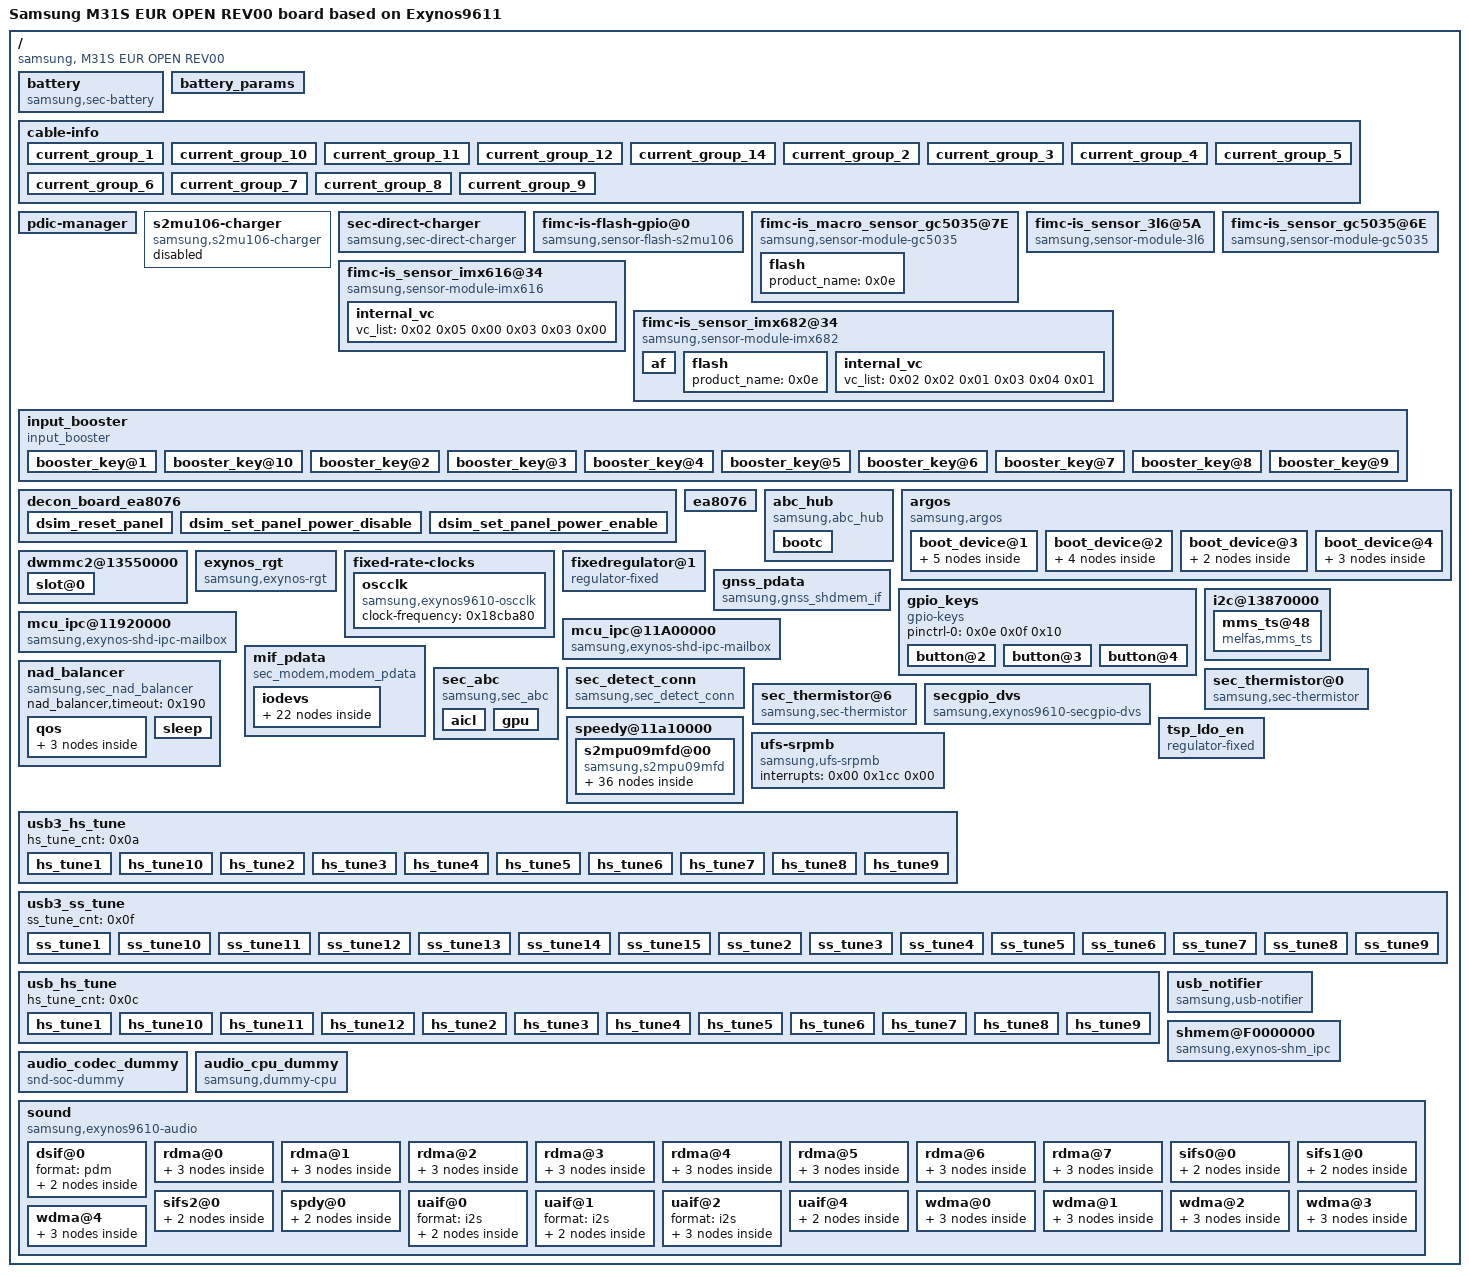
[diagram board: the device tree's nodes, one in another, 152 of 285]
/dts-v1/;

/ {
	compatible = "samsung, M31S EUR OPEN REV00\0samsung,EXYNOS9611";
	dtbo-hw_rev = <0x00>;
	dtbo-hw_rev_end = <0xff>;

	__fixups__ {
		abox = "/fragment@sound/__overlay__/sound:samsung,codec:0\0/fragment@sound/__overlay__/sound/rdma@0/cpu:sound-dai:0\0/fragment@sound/__overlay__/sound/rdma@1/cpu:sound-dai:0\0/fragment@sound/__overlay__/sound/rdma@2/cpu:sound-dai:0\0/fragment@sound/__overlay__/sound/rdma@3/cpu:sound-dai:0\0/fragment@sound/__overlay__/sound/rdma@4/cpu:sound-dai:0\0/fragment@sound/__overlay__/sound/rdma@5/cpu:sound-dai:0\0/fragment@sound/__overlay__/sound/rdma@6/cpu:sound-dai:0\0/fragment@sound/__overlay__/sound/rdma@7/cpu:sound-dai:0\0/fragment@sound/__overlay__/sound/wdma@0/cpu:sound-dai:0\0/fragment@sound/__overlay__/sound/wdma@1/cpu:sound-dai:0\0/fragment@sound/__overlay__/sound/wdma@2/cpu:sound-dai:0\0/fragment@sound/__overlay__/sound/wdma@3/cpu:sound-dai:0\0/fragment@sound/__overlay__/sound/wdma@4/cpu:sound-dai:0\0/fragment@sound/__overlay__/sound/sifs0@0/cpu:sound-dai:0\0/fragment@sound/__overlay__/sound/sifs1@0/cpu:sound-dai:0\0/fragment@sound/__overlay__/sound/sifs2@0/cpu:sound-dai:0\0/fragment@15:target:0";
		abox_bt = "/fragment@sound/__overlay__/sound:samsung,aux:4";
		abox_dsif = "/fragment@sound/__overlay__/sound:samsung,codec:20\0/fragment@sound/__overlay__/sound/dsif@0/cpu:sound-dai:0";
		abox_effect = "/fragment@sound/__overlay__/sound:samsung,aux:0";
		abox_rdma_0 = "/fragment@sound/__overlay__/sound/rdma@0/platform:sound-dai:0";
		abox_rdma_1 = "/fragment@sound/__overlay__/sound/rdma@1/platform:sound-dai:0";
		abox_rdma_2 = "/fragment@sound/__overlay__/sound/rdma@2/platform:sound-dai:0";
		abox_rdma_3 = "/fragment@sound/__overlay__/sound/rdma@3/platform:sound-dai:0";
		abox_rdma_4 = "/fragment@sound/__overlay__/sound/rdma@4/platform:sound-dai:0";
		abox_rdma_5 = "/fragment@sound/__overlay__/sound/rdma@5/platform:sound-dai:0";
		abox_rdma_6 = "/fragment@sound/__overlay__/sound/rdma@6/platform:sound-dai:0";
		abox_rdma_7 = "/fragment@sound/__overlay__/sound/rdma@7/platform:sound-dai:0";
		abox_spdy = "/fragment@sound/__overlay__/sound:samsung,codec:24\0/fragment@sound/__overlay__/sound/spdy@0/cpu:sound-dai:0";
		abox_synchronized_ipc = "/fragment@sound/__overlay__/sound/uaif@2/platform:sound-dai:0";
		abox_uaif_0 = "/fragment@sound/__overlay__/sound:samsung,codec:4\0/fragment@sound/__overlay__/sound/uaif@0/cpu:sound-dai:0";
		abox_uaif_1 = "/fragment@sound/__overlay__/sound:samsung,codec:8\0/fragment@sound/__overlay__/sound/uaif@1/cpu:sound-dai:0";
		abox_uaif_2 = "/fragment@sound/__overlay__/sound:samsung,codec:12\0/fragment@sound/__overlay__/sound/uaif@2/cpu:sound-dai:0";
		abox_uaif_4 = "/fragment@sound/__overlay__/sound:samsung,codec:16\0/fragment@sound/__overlay__/sound/uaif@4/cpu:sound-dai:0";
		abox_wdma_0 = "/fragment@sound/__overlay__/sound/wdma@0/platform:sound-dai:0";
		abox_wdma_1 = "/fragment@sound/__overlay__/sound/wdma@1/platform:sound-dai:0";
		abox_wdma_2 = "/fragment@sound/__overlay__/sound/wdma@2/platform:sound-dai:0";
		abox_wdma_3 = "/fragment@sound/__overlay__/sound/wdma@3/platform:sound-dai:0";
		abox_wdma_4 = "/fragment@sound/__overlay__/sound/wdma@4/platform:sound-dai:0";
		android_q_fstab = "/fragment@23:target:0";
		chosen = "/fragment@47:target:0";
		clock = "/fragment@sound/__overlay__/sound:clocks:0\0/fragment@52/__overlay__:clocks:0\0/fragment@52/__overlay__:clocks:8\0/fragment@55/__overlay__/sec-nfc@27:clocks:0";
		contexthub_0 = "/fragment@52:target:0";
		decon_f = "/fragment@1:target:0";
		dsim_0 = "/fragment@0:target:0";
		exynos_adc = "/fragment@battery/__overlay__/battery:io-channels:0\0/fragment@battery/__overlay__/battery:io-channels:8\0/fragment@model/__overlay__/sec_thermistor@0:io-channels:0\0/fragment@model/__overlay__/sec_thermistor@6:io-channels:0";
		fimc_is = "/fragment@2:target:0";
		fimc_is_mclk0_fn = "/fragment@camera/__overlay__/fimc-is_sensor_imx682@34:pinctrl-1:0\0/fragment@camera/__overlay__/fimc-is_sensor_gc5035@6E:pinctrl-2:0";
		fimc_is_mclk0_out = "/fragment@camera/__overlay__/fimc-is_sensor_imx682@34:pinctrl-0:0\0/fragment@camera/__overlay__/fimc-is_sensor_gc5035@6E:pinctrl-1:0\0/fragment@2/__overlay__:pinctrl-0:0";
		fimc_is_mclk1_fn = "/fragment@camera/__overlay__/fimc-is_sensor_imx616@34:pinctrl-2:0";
		fimc_is_mclk1_out = "/fragment@camera/__overlay__/fimc-is_sensor_imx616@34:pinctrl-1:0\0/fragment@2/__overlay__:pinctrl-0:4";
		fimc_is_mclk2_fn = "/fragment@camera/__overlay__/fimc-is_sensor_3l6@5A:pinctrl-2:0\0/fragment@camera/__overlay__/fimc-is_macro_sensor_gc5035@7E:pinctrl-2:0";
		fimc_is_mclk2_out = "/fragment@camera/__overlay__/fimc-is_sensor_3l6@5A:pinctrl-1:0\0/fragment@camera/__overlay__/fimc-is_macro_sensor_gc5035@7E:pinctrl-1:0\0/fragment@2/__overlay__:pinctrl-0:8";
		fimc_is_sensor0 = "/fragment@10:target:0";
		fimc_is_sensor1 = "/fragment@11:target:0";
		fimc_is_sensor2 = "/fragment@12:target:0";
		fimc_is_sensor3 = "/fragment@13:target:0";
		fimc_is_sensor4 = "/fragment@14:target:0";
		fmp_0 = "/fragment@31:target:0";
		gnss_reserved = "/fragment@model/__overlay__/gnss_pdata:memory-region:0";
		gpa0 = "/fragment@lcd/__overlay__/decon_board_ea8076:gpio_det:0\0/fragment@lcd/__overlay__/decon_board_ea8076:gpio_con:0\0/fragment@model/__overlay__/i2c@13870000/mms_ts@48:melfas,irq-gpio:0\0/fragment@model/__overlay__/sec_detect_conn:sec,det_conn_gpios:0\0/fragment@62/__overlay__/etspi-spi@0:etspi-drdyPin:0\0/fragment@63/__overlay__/isg5320a@28:interrupt-parent:0\0/fragment@63/__overlay__/isg5320a@28:isg5320a,irq-gpio:0";
		gpa1 = "/fragment@lcd/__overlay__/decon_board_ea8076:gpio_err:0\0/fragment@camera/__overlay__/fimc-is-flash-gpio@0:torch-gpio:0\0/fragment@9/__overlay__/s2mu106@3D/flash_led:torch-gpio:0\0/fragment@17/__overlay__/rt5665@1b:interrupt-parent:0\0/fragment@20/__overlay__/sm5440@63:sm5440,irq-gpio:0\0/fragment@model/__overlay__/gpio_keys/button@2:gpios:0\0/fragment@model/__overlay__/gpio_keys/button@3:gpios:0\0/fragment@model/__overlay__/gpio_keys/button@4:gpios:0\0/fragment@55/__overlay__/sec-nfc@27:interrupt-parent:0\0/fragment@55/__overlay__/sec-nfc@27:sec-nfc,irq-gpio:0";
		gpa2 = "/fragment@lcd/__overlay__/decon_board_ea8076:gpio_pcd:0\0/fragment@model/__overlay__/speedy@11a10000/s2mpu09mfd@00:s2mpu09,irq-gpio:0\0/fragment@model/__overlay__/speedy@11a10000/s2mpu09mfd@00:interrupt-parent:0\0/fragment@model/__overlay__/dwmmc2@13550000:card-detect:0\0/fragment@48/__overlay__/usbpd-s2mu106@3C:usbpd,usbpd_int:0\0/fragment@49/__overlay__/s2mu106@3D:s2mu106,irq-gpio:0\0/fragment@49/__overlay__/s2mu106@3A/s2mu106-haptic:haptic,motor_en:0\0/fragment@55/__overlay__/sec-nfc@27:sec-nfc,clk_req-gpio:0\0/fragment@63/__overlay__/isg5320a_sub@2C:interrupt-parent:0\0/fragment@63/__overlay__/isg5320a_sub@2C:isg5320a_sub,irq-gpio:0";
		gpc0 = "/fragment@3/__overlay__:gpios:0\0/fragment@3/__overlay__:gpios:12\0/fragment@4/__overlay__:gpios:0\0/fragment@4/__overlay__:gpios:12\0/fragment@5/__overlay__:gpios:0\0/fragment@5/__overlay__:gpios:12\0/fragment@6/__overlay__:gpios:0\0/fragment@6/__overlay__:gpios:12";
		gpc1 = "/fragment@7/__overlay__:gpios:0\0/fragment@7/__overlay__:gpios:12\0/fragment@8/__overlay__:gpios:0\0/fragment@8/__overlay__:gpios:12";
		gpc2 = "/fragment@camera/__overlay__/fimc-is_sensor_imx682@34:gpio_mclk:0\0/fragment@camera/__overlay__/fimc-is_sensor_gc5035@6E:gpio_mclk:0\0/fragment@camera/__overlay__/fimc-is_sensor_3l6@5A:gpio_mclk:0\0/fragment@camera/__overlay__/fimc-is_macro_sensor_gc5035@7E:gpio_mclk:0\0/fragment@camera/__overlay__/fimc-is_sensor_imx616@34:gpio_mclk:0";
		gpg0 = "/fragment@camera/__overlay__/fimc-is_sensor_imx682@34:gpio_ldo_en:0\0/fragment@camera/__overlay__/fimc-is-flash-gpio@0:flash-gpio:0\0/fragment@camera/__overlay__/fimc-is_sensor_gc5035@6E:gpio_reset:0\0/fragment@camera/__overlay__/fimc-is_macro_sensor_gc5035@7E:gpio_reset:0\0/fragment@9/__overlay__/s2mu106@3D/flash_led:flash-gpio:0\0/fragment@55/__overlay__/sec-nfc@27:sec-nfc,ven-gpio:0\0/fragment@55/__overlay__/sec-nfc@27:sec-nfc,check_nfc:0";
		gpg1 = "/fragment@lcd/__overlay__/decon_board_ea8076:gpio_lcd_rst:0\0/fragment@lcd/__overlay__/decon_board_ea8076:gpio_lcd_en_1p8:0\0/fragment@camera/__overlay__/fimc-is_sensor_imx682@34:gpio_reset:0\0/fragment@camera/__overlay__/fimc-is_sensor_3l6@5A:gpio_reset:0\0/fragment@camera/__overlay__/fimc-is_sensor_3l6@5A:gpio_ldo_en:0\0/fragment@camera/__overlay__/fimc-is_sensor_imx616@34:gpio_reset:0\0/fragment@55/__overlay__/sec-nfc@27:sec-nfc,firm-gpio:0";
		gpg2 = "/fragment@lcd/__overlay__/decon_board_ea8076:gpio_lcd_en_3p0:0";
		gpg3 = "/fragment@model/__overlay__/mif_pdata:gpios:0\0/fragment@model/__overlay__/mif_pdata:gpios:12\0/fragment@model/__overlay__/mif_pdata:gpios:24\0/fragment@model/__overlay__/mif_pdata:gpios:36\0/fragment@model/__overlay__/tsp_ldo_en:gpio:0\0/fragment@62/__overlay__/etspi-spi@0:etspi-sleepPin:0";
		gpm20 = "/fragment@21/__overlay__/s2mu106-fuelgauge@3B:fuelgauge,fuel_int:0";
		gpm21 = "/fragment@52/__overlay__:sensor-ldo-en:0";
		gpm22 = "/fragment@camera/__overlay__/fimc-is_macro_sensor_gc5035@7E:gpio_cam_a2p8_1p2_en:0";
		gpp1 = "/fragment@model/__overlay__/i2c@13870000/mms_ts@48:melfas,scl-gpio:0\0/fragment@model/__overlay__/i2c@13870000/mms_ts@48:melfas,sda-gpio:0";
		gpp2 = "/fragment@62/__overlay__/etspi-spi@0/controller-data:cs-gpio:0";
		hsi2c12_bus = "/fragment@3/__overlay__:pinctrl-0:0\0/fragment@3/__overlay__:pinctrl-1:0\0/fragment@3/__overlay__:pinctrl-2:0";
		hsi2c13_bus = "/fragment@4/__overlay__:pinctrl-0:0\0/fragment@4/__overlay__:pinctrl-1:0\0/fragment@4/__overlay__:pinctrl-2:0";
		hsi2c14_bus = "/fragment@5/__overlay__:pinctrl-0:0\0/fragment@5/__overlay__:pinctrl-1:0\0/fragment@5/__overlay__:pinctrl-2:0";
		hsi2c15_bus = "/fragment@6/__overlay__:pinctrl-0:0\0/fragment@6/__overlay__:pinctrl-1:0\0/fragment@6/__overlay__:pinctrl-2:0";
		hsi2c16_bus = "/fragment@7/__overlay__:pinctrl-0:0\0/fragment@7/__overlay__:pinctrl-1:0\0/fragment@7/__overlay__:pinctrl-2:0";
		hsi2c17_bus = "/fragment@8/__overlay__:pinctrl-0:0\0/fragment@8/__overlay__:pinctrl-1:0\0/fragment@8/__overlay__:pinctrl-2:0";
		hsi2c_12 = "/fragment@3:target:0";
		hsi2c_13 = "/fragment@4:target:0";
		hsi2c_14 = "/fragment@5:target:0";
		hsi2c_15 = "/fragment@6:target:0";
		hsi2c_16 = "/fragment@7:target:0";
		hsi2c_17 = "/fragment@8:target:0";
		hsi2c_3 = "/fragment@16:target:0";
		hsi2c_6 = "/fragment@55:target:0";
		i2c_0 = "/fragment@21:target:0\0/fragment@48:target:0";
		i2c_1 = "/fragment@9:target:0\0/fragment@20:target:0\0/fragment@49:target:0";
		i2c_3 = "/fragment@50:target:0";
		i2c_5 = "/fragment@63:target:0";
		i2c_6 = "/fragment@17:target:0";
		mipi_phy_csis_m2s4s4s2 = "/fragment@11/__overlay__:phys:0\0/fragment@13/__overlay__:phys:0";
		pdma0 = "/fragment@62/__overlay__:dmas:0\0/fragment@62/__overlay__:dmas:8";
		pinctrl_0 = "/fragment@19:target:0\0/fragment@29:target:0\0/fragment@53:target:0\0/fragment@56:target:0\0/fragment@60:target:0\0/fragment@64:target:0";
		pinctrl_1 = "/fragment@18:target:0\0/fragment@57:target:0";
		pinctrl_2 = "/fragment@58:target:0";
		pinctrl_4 = "/fragment@30:target:0\0/fragment@54:target:0\0/fragment@59:target:0\0/fragment@61:target:0";
		reserved_memory = "/fragment@51:target:0";
		sd2_bus1 = "/fragment@model/__overlay__/dwmmc2@13550000:pinctrl-0:8";
		sd2_bus4 = "/fragment@model/__overlay__/dwmmc2@13550000:pinctrl-0:12";
		sd2_clk = "/fragment@model/__overlay__/dwmmc2@13550000:pinctrl-0:0";
		sd2_clk_fast_slew_rate_1x = "/fragment@model/__overlay__/dwmmc2@13550000:pinctrl-1:0";
		sd2_clk_fast_slew_rate_2x = "/fragment@model/__overlay__/dwmmc2@13550000:pinctrl-2:0";
		sd2_clk_fast_slew_rate_3x = "/fragment@model/__overlay__/dwmmc2@13550000:pinctrl-3:0";
		sd2_clk_fast_slew_rate_4x = "/fragment@model/__overlay__/dwmmc2@13550000:pinctrl-4:0";
		sd2_cmd = "/fragment@model/__overlay__/dwmmc2@13550000:pinctrl-0:4";
		serial_0 = "/fragment@28:target:0";
		shared_meta = "/fragment@22:target:0";
		spi_7 = "/fragment@62:target:0";
		udc = "/fragment@model/__overlay__/usb_notifier:udc:0\0/fragment@24:target:0";
		usbdrd3_phy = "/fragment@27:target:0";
		usbdrd_dwc3 = "/fragment@25:target:0";
		usbdrd_phy = "/fragment@26:target:0";
		usi_0_cmgp = "/fragment@34:target:0";
		usi_0_cmgp_i2c = "/fragment@35:target:0";
		usi_0_shub = "/fragment@32:target:0";
		usi_0_shub_i2c = "/fragment@33:target:0";
		usi_1_cmgp = "/fragment@36:target:0";
		usi_1_cmgp_i2c = "/fragment@37:target:0";
		usi_2_cmgp = "/fragment@38:target:0";
		usi_2_cmgp_i2c = "/fragment@39:target:0";
		usi_3_cmgp = "/fragment@40:target:0";
		usi_3_cmgp_i2c = "/fragment@41:target:0";
		usi_4_cmgp = "/fragment@42:target:0";
		usi_4_cmgp_i2c = "/fragment@43:target:0";
		usi_peri_spi_1 = "/fragment@46:target:0";
		usi_peri_usi_0 = "/fragment@44:target:0";
		usi_peri_usi_0_i2c = "/fragment@45:target:0";
		xclkout0 = "/fragment@sound/__overlay__/sound:pinctrl-0:0";
		xclkout1 = "/fragment@55/__overlay__/sec-nfc@27:pinctrl-0:8";
	};

	__local_fixups__ {

		fragment@0 {

			__overlay__ {
				lcd_info = <0x00>;
			};
		};

		fragment@17 {

			__overlay__ {

				rt5665@1b {
					pinctrl-0 = <0x00>;
					realtek,regulator_1v8 = <0x00>;
					realtek,regulator_3v3 = <0x00>;
				};
			};
		};

		fragment@20 {

			__overlay__ {

				sm5440@63 {
					pinctrl-0 = <0x00>;
				};
			};
		};

		fragment@21 {

			__overlay__ {

				s2mu106-fuelgauge@3B {
					pinctrl-0 = <0x00>;
				};
			};
		};

		fragment@26 {

			__overlay__ {
				hs_tune_param = <0x00>;
			};
		};

		fragment@27 {

			__overlay__ {
				hs_tune_param = <0x00>;
				ss_tune_param = <0x00>;
			};
		};

		fragment@48 {

			__overlay__ {

				usbpd-s2mu106@3C {
					pinctrl-0 = <0x00>;
				};
			};
		};

		fragment@49 {

			__overlay__ {

				s2mu106@3A {

					s2mu106-haptic {
						pinctrl-0 = <0x00>;
					};
				};

				s2mu106@3D {
					pinctrl-0 = <0x00>;
				};
			};
		};

		fragment@55 {

			__overlay__ {

				sec-nfc@27 {
					pinctrl-0 = <0x00 0x04 0x0c 0x10>;
					pinctrl-1 = <0x00 0x04 0x08 0x0c>;
				};
			};
		};

		fragment@56 {

			__overlay__ {
				pinctrl-0 = <0x00>;
			};
		};

		fragment@57 {

			__overlay__ {
				pinctrl-0 = <0x00>;
				pinctrl-1 = <0x00>;
			};
		};

		fragment@58 {

			__overlay__ {
				pinctrl-0 = <0x00>;
			};
		};

		fragment@59 {

			__overlay__ {
				pinctrl-0 = <0x00>;
				pinctrl-1 = <0x00>;
			};
		};

		fragment@62 {

			__overlay__ {

				etspi-spi@0 {
					pinctrl-0 = <0x00 0x04>;
					pinctrl-1 = <0x00 0x04 0x08 0x0c 0x10>;
					pinctrl-2 = <0x00 0x04 0x08>;
					pinctrl-3 = <0x00>;
					pinctrl-4 = <0x00>;
				};
			};
		};

		fragment@63 {

			__overlay__ {

				isg5320a@28 {
					pinctrl-0 = <0x00>;
				};

				isg5320a_sub@2C {
					pinctrl-0 = <0x00>;
				};
			};
		};

		fragment@lcd {

			__overlay__ {

				ea8076 {
					decon_board = <0x00>;
				};
			};
		};

		fragment@model {

			__overlay__ {

				dwmmc2@13550000 {
					pinctrl-0 = <0x10>;
				};

				gnss_pdata {
					mbox_info = <0x00>;
				};

				gpio_keys {
					pinctrl-0 = <0x00 0x04 0x08>;
				};

				i2c@13870000 {

					mms_ts@48 {
						pinctrl-0 = <0x00>;
						pinctrl-1 = <0x00>;
					};
				};

				sec_detect_conn {
					pinctrl-0 = <0x00>;
				};

				speedy@11a10000 {

					s2mpu09mfd@00 {
						pinctrl-0 = <0x00 0x04>;
					};
				};
			};
		};

		fragment@sound {

			__overlay__ {

				sound {

					dsif@0 {

						codec {
							sound-dai = <0x00>;
						};
					};

					rdma@0 {

						codec {
							sound-dai = <0x00>;
						};
					};

					rdma@1 {

						codec {
							sound-dai = <0x00>;
						};
					};

					rdma@2 {

						codec {
							sound-dai = <0x00>;
						};
					};

					rdma@3 {

						codec {
							sound-dai = <0x00>;
						};
					};

					rdma@4 {

						codec {
							sound-dai = <0x00>;
						};
					};

					rdma@5 {

						codec {
							sound-dai = <0x00>;
						};
					};

					rdma@6 {

						codec {
							sound-dai = <0x00>;
						};
					};

					rdma@7 {

						codec {
							sound-dai = <0x00>;
						};
					};

					sifs0@0 {

						codec {
							sound-dai = <0x00>;
						};
					};

					sifs1@0 {

						codec {
							sound-dai = <0x00>;
						};
					};

					sifs2@0 {

						codec {
							sound-dai = <0x00>;
						};
					};

					spdy@0 {

						codec {
							sound-dai = <0x00>;
						};
					};

					uaif@0 {

						codec {
							sound-dai = <0x00>;
						};
					};

					uaif@1 {

						codec {
							sound-dai = <0x00>;
						};
					};

					uaif@2 {

						codec {
							sound-dai = <0x00>;
						};
					};

					uaif@4 {

						codec {
							sound-dai = <0x00>;
						};
					};

					wdma@0 {

						codec {
							sound-dai = <0x00>;
						};
					};

					wdma@1 {

						codec {
							sound-dai = <0x00>;
						};
					};

					wdma@2 {

						codec {
							sound-dai = <0x00>;
						};
					};

					wdma@3 {

						codec {
							sound-dai = <0x00>;
						};
					};

					wdma@4 {

						codec {
							sound-dai = <0x00>;
						};
					};
				};
			};
		};
	};

	__symbols__ {
		V_SYS = "/fragment@model/__overlay__/fixedregulator@1";
		__ldo1_reg = "/fragment@50/__overlay__/s2mpb03@56/regulators/s2mpb03-ldo1";
		__ldo2_reg = "/fragment@50/__overlay__/s2mpb03@56/regulators/s2mpb03-ldo2";
		__ldo3_reg = "/fragment@50/__overlay__/s2mpb03@56/regulators/s2mpb03-ldo3";
		__ldo4_reg = "/fragment@50/__overlay__/s2mpb03@56/regulators/s2mpb03-ldo4";
		__ldo5_reg = "/fragment@50/__overlay__/s2mpb03@56/regulators/s2mpb03-ldo5";
		__ldo6_reg = "/fragment@50/__overlay__/s2mpb03@56/regulators/s2mpb03-ldo6";
		__ldo7_reg = "/fragment@50/__overlay__/s2mpb03@56/regulators/s2mpb03-ldo7";
		attn_input = "/fragment@29/__overlay__/attn-input";
		attn_irq = "/fragment@29/__overlay__/attn-irq";
		b1_reg = "/fragment@model/__overlay__/speedy@11a10000/s2mpu09mfd@00/regulators/BUCK1";
		b2_reg = "/fragment@model/__overlay__/speedy@11a10000/s2mpu09mfd@00/regulators/BUCK2";
		b3_reg = "/fragment@model/__overlay__/speedy@11a10000/s2mpu09mfd@00/regulators/BUCK3";
		b4_reg = "/fragment@model/__overlay__/speedy@11a10000/s2mpu09mfd@00/regulators/BUCK4";
		b5_reg = "/fragment@model/__overlay__/speedy@11a10000/s2mpu09mfd@00/regulators/BUCK5";
		b6_reg = "/fragment@model/__overlay__/speedy@11a10000/s2mpu09mfd@00/regulators/BUCK6";
		b7_reg = "/fragment@model/__overlay__/speedy@11a10000/s2mpu09mfd@00/regulators/BUCK7";
		b8_reg = "/fragment@model/__overlay__/speedy@11a10000/s2mpu09mfd@00/regulators/BUCK8";
		b9_reg = "/fragment@model/__overlay__/speedy@11a10000/s2mpu09mfd@00/regulators/BUCK9";
		btp_irq = "/fragment@60/__overlay__/btp-irq";
		btp_irq_sleep = "/fragment@60/__overlay__/btp-irq-sleep";
		btp_rst = "/fragment@61/__overlay__/btp-rst";
		codec_irq = "/fragment@29/__overlay__/codec_irq";
		dc_irq = "/fragment@19/__overlay__/dc-irq";
		decon_board_ea8076 = "/fragment@lcd/__overlay__/decon_board_ea8076";
		dummy_audio_codec = "/fragment@sound/__overlay__/audio_codec_dummy";
		dummy_audio_cpu = "/fragment@sound/__overlay__/audio_cpu_dummy";
		dwmmc2_cd_ext_irq = "/fragment@29/__overlay__/dwmmc2_cd_ext_irq";
		ea8076 = "/fragment@lcd/__overlay__/ea8076";
		ext_bin_0 = "/fragment@15/__overlay__/ext_bin@0";
		ext_bin_1 = "/fragment@15/__overlay__/ext_bin@1";
		ext_bin_2 = "/fragment@15/__overlay__/ext_bin@2";
		ext_bin_4 = "/fragment@15/__overlay__/ext_bin@4";
		ext_bin_5 = "/fragment@15/__overlay__/ext_bin@5";
		fimc_is_flash_gpio = "/fragment@camera/__overlay__/fimc-is-flash-gpio@0";
		fimc_is_macro_module_gc5035 = "/fragment@camera/__overlay__/fimc-is_macro_sensor_gc5035@7E";
		fimc_is_module_gc5035 = "/fragment@camera/__overlay__/fimc-is_sensor_gc5035@6E";
		fimc_is_sensor_3l6 = "/fragment@camera/__overlay__/fimc-is_sensor_3l6@5A";
		fimc_is_sensor_imx616 = "/fragment@camera/__overlay__/fimc-is_sensor_imx616@34";
		fimc_is_sensor_imx682 = "/fragment@camera/__overlay__/fimc-is_sensor_imx682@34";
		fuel_irq = "/fragment@18/__overlay__/fuel-irq";
		grip_int = "/fragment@64/__overlay__/grip-int";
		grip_sub_int = "/fragment@64/__overlay__/grip-sub-int";
		i2c_4 = "/fragment@model/__overlay__/i2c@13870000";
		if_pmic_irq = "/fragment@29/__overlay__/if-pmic-irq";
		initial0 = "/fragment@56/__overlay__/initial-state";
		initial1 = "/fragment@57/__overlay__/initial-state";
		initial4 = "/fragment@59/__overlay__/initial-state";
		key_power = "/fragment@29/__overlay__/key-power";
		key_voldown = "/fragment@29/__overlay__/key-voldown";
		key_volup = "/fragment@29/__overlay__/key-volup";
		l10_reg = "/fragment@model/__overlay__/speedy@11a10000/s2mpu09mfd@00/regulators/LDO10";
		l11_reg = "/fragment@model/__overlay__/speedy@11a10000/s2mpu09mfd@00/regulators/LDO11";
		l12_reg = "/fragment@model/__overlay__/speedy@11a10000/s2mpu09mfd@00/regulators/LDO12";
		l13_reg = "/fragment@model/__overlay__/speedy@11a10000/s2mpu09mfd@00/regulators/LDO13";
		l14_reg = "/fragment@model/__overlay__/speedy@11a10000/s2mpu09mfd@00/regulators/LDO14";
		l1_reg = "/fragment@model/__overlay__/speedy@11a10000/s2mpu09mfd@00/regulators/LDO1";
		l2_reg = "/fragment@model/__overlay__/speedy@11a10000/s2mpu09mfd@00/regulators/LDO2";
		l33_reg = "/fragment@model/__overlay__/speedy@11a10000/s2mpu09mfd@00/regulators/LDO33";
		l34_reg = "/fragment@model/__overlay__/speedy@11a10000/s2mpu09mfd@00/regulators/LDO34";
		l35_reg = "/fragment@model/__overlay__/speedy@11a10000/s2mpu09mfd@00/regulators/LDO35";
		l36_reg = "/fragment@model/__overlay__/speedy@11a10000/s2mpu09mfd@00/regulators/LDO36";
		l37_reg = "/fragment@model/__overlay__/speedy@11a10000/s2mpu09mfd@00/regulators/LDO37";
		l38_reg = "/fragment@model/__overlay__/speedy@11a10000/s2mpu09mfd@00/regulators/LDO38";
		l39_reg = "/fragment@model/__overlay__/speedy@11a10000/s2mpu09mfd@00/regulators/LDO39";
		l3_reg = "/fragment@model/__overlay__/speedy@11a10000/s2mpu09mfd@00/regulators/LDO3";
		l40_reg = "/fragment@model/__overlay__/speedy@11a10000/s2mpu09mfd@00/regulators/LDO40";
		l41_reg = "/fragment@model/__overlay__/speedy@11a10000/s2mpu09mfd@00/regulators/LDO41";
		l42_reg = "/fragment@model/__overlay__/speedy@11a10000/s2mpu09mfd@00/regulators/LDO42";
		l43_reg = "/fragment@model/__overlay__/speedy@11a10000/s2mpu09mfd@00/regulators/LDO43";
		l44_reg = "/fragment@model/__overlay__/speedy@11a10000/s2mpu09mfd@00/regulators/LDO44";
		l4_reg = "/fragment@model/__overlay__/speedy@11a10000/s2mpu09mfd@00/regulators/LDO4";
		l5_reg = "/fragment@model/__overlay__/speedy@11a10000/s2mpu09mfd@00/regulators/LDO5";
		l6_reg = "/fragment@model/__overlay__/speedy@11a10000/s2mpu09mfd@00/regulators/LDO6";
		l7_reg = "/fragment@model/__overlay__/speedy@11a10000/s2mpu09mfd@00/regulators/LDO7";
		l8_reg = "/fragment@model/__overlay__/speedy@11a10000/s2mpu09mfd@00/regulators/LDO8";
		l9_reg = "/fragment@model/__overlay__/speedy@11a10000/s2mpu09mfd@00/regulators/LDO9";
		mailbox_cp = "/fragment@model/__overlay__/mcu_ipc@11920000";
		mailbox_gnss = "/fragment@model/__overlay__/mcu_ipc@11A00000";
		motor_en = "/fragment@29/__overlay__/motor-en";
		nfc_check = "/fragment@54/__overlay__/nfc-check";
		nfc_clk_req = "/fragment@53/__overlay__/nfc_clk_req";
		nfc_clk_req_nc = "/fragment@53/__overlay__/nfc_clk_req_nc";
		nfc_en = "/fragment@54/__overlay__/nfc_en";
		nfc_en_nc = "/fragment@54/__overlay__/nfc_en_nc";
		nfc_firm = "/fragment@54/__overlay__/nfc_firm";
		nfc_firm_nc = "/fragment@54/__overlay__/nfc_firm_nc";
		pm_wrsti = "/fragment@30/__overlay__/pm-wrsti";
		pmic_irq = "/fragment@29/__overlay__/pmic-irq";
		rt5510_amp = "/fragment@16/__overlay__/rt5510@34";
		rt5665 = "/fragment@17/__overlay__/rt5665@1b";
		sensor3_ch_mode0 = "/fragment@13/__overlay__/sensor3-ch-mode0";
		shmem = "/fragment@modemif/__overlay__/shmem@F0000000";
		sleep1 = "/fragment@57/__overlay__/sleep-state";
		sleep2 = "/fragment@58/__overlay__/sleep-state";
		sleep4 = "/fragment@59/__overlay__/sleep-state";
		spi7_bus_inactive = "/fragment@61/__overlay__/spi7-bus-inactive";
		spi7_clk = "/fragment@61/__overlay__/spi7-clk";
		spi7_cs = "/fragment@61/__overlay__/spi7-cs";
		spi7_miso = "/fragment@61/__overlay__/spi7-miso";
		spi7_miso_inactive = "/fragment@61/__overlay__/spi17-miso-inactive";
		spi7_mosi = "/fragment@61/__overlay__/spi7-mosi";
		sub_detect_conn_setting = "/fragment@29/__overlay__/sub_detect_conn_setting";
		usb3_hs_tune = "/fragment@model/__overlay__/usb3_hs_tune";
		usb3_ss_tune = "/fragment@model/__overlay__/usb3_ss_tune";
		usb_hs_tune = "/fragment@model/__overlay__/usb_hs_tune";
		usbpd_irq = "/fragment@29/__overlay__/usbpd-irq";
		xclkout1_nc = "/fragment@53/__overlay__/xclkout1_nc";
	};

	fragment@0 {
		target = <0xffffffff>;

		__overlay__ {
			lcd_info = <0x02>;
		};
	};

	fragment@1 {
		target = <0xffffffff>;

		__overlay__ {
			dsi_mode = <0x00>;
			psr_mode = <0x02>;
			trig_mode = <0x00>;
		};
	};

	fragment@10 {
		target = <0xffffffff>;

		__overlay__ {
			camif_mux_val = <0x182077>;
			csi_ch = <0x00>;
			csi_mux = <0x02>;
			dma_ch = <0x00 0x00 0x00 0x00 0x00 0x00 0x02 0x00>;
			flite_ch = <0x64>;
			id = <0x00>;
			is_bns = <0x00>;
			multi_ch = <0x02>;
			scenario = <0x00>;
			status = "okay";
			use_ssvc2_internal;
			use_ssvc3_internal;
			vc_ch = <0x00 0x01 0x02 0x03 0x00 0x01 0x00 0x03>;
		};
	};

	fragment@11 {
		target = <0xffffffff>;

		__overlay__ {
			camif_mux_val = <0x182077>;
			csi_ch = <0x01>;
			csi_mux = <0x02>;
			dma_ch = <0x01 0x01 0x01 0x01 0x02 0x02 0x02 0x02>;
			flite_ch = <0x64>;
			id = <0x02>;
			is_bns = <0x00>;
			multi_ch = <0x02>;
			phys = <0xffffffff 0x01>;
			scenario = <0x00>;
			status = "okay";
			vc_ch = <0x00 0x01 0x02 0x03 0x01 0x02 0x01 0x03>;
		};
	};

	fragment@12 {
		target = <0xffffffff>;

		__overlay__ {
			camif_mux_val = <0x2077>;
			camif_mux_val_s = <0x184240>;
			csi_ch = <0x02>;
			csi_mux = <0x02>;
			dma_ch = <0x02 0x02 0x02 0x02>;
			flite_ch = <0x64>;
			id = <0x01>;
			is_bns = <0x00>;
			multi_ch = <0x00>;
			scenario = <0x00>;
			status = "okay";
			use_ssvc2_internal;
			use_ssvc3_internal;
			vc_ch = <0x00 0x01 0x02 0x03>;
		};
	};

	fragment@13 {
		target = <0xffffffff>;

		__overlay__ {
			camif_mux_val = <0x182077>;
			csi_ch = <0x01>;
			csi_mux = <0x00>;
			dma_ch = <0x01 0x01 0x01 0x01>;
			flite_ch = <0x64>;
			id = <0x03>;
			interrupt-names = "csi\0mode0_VC0\0mode0_VC1\0mode0_VC2\0mode0_VC3";
			interrupts = <0x00 0x146 0x00 0x00 0x14c 0x00 0x00 0x14c 0x00 0x00 0x14c 0x00 0x00 0x14c 0x00>;
			is_bns = <0x00>;
			multi_ch = <0x02>;
			phys = <0xffffffff 0x00>;
			reg = <0x00 0x14410700 0x100 0x00 0x14410000 0x700>;
			reg-names = "phy\0csi";
			scenario = <0x00>;
			status = "okay";
			vc_ch = <0x00 0x01 0x02 0x03>;

			sensor3-ch-mode0 {
				linux,phandle = <0x3b>;
				phandle = <0x3b>;
				reg = <0x14460000 0x100 0x14460400 0x100 0x14460100 0x100 0x14460400 0x100 0x14460200 0x100 0x14460400 0x100 0x14460300 0x100 0x14460400 0x100>;
			};
		};
	};

	fragment@14 {
		target = <0xffffffff>;

		__overlay__ {
			camif_mux_val = <0x60ff>;
			csi_ch = <0x03>;
			csi_mux = <0x00>;
			dma_ch = <0x03 0x03 0x03 0x03>;
			flite_ch = <0x64>;
			id = <0x04>;
			is_bns = <0x00>;
			multi_ch = <0x00>;
			scenario = <0x00>;
			status = "okay";
			vc_ch = <0x00 0x01 0x02 0x03>;
		};
	};

	fragment@15 {
		target = <0xffffffff>;

		__overlay__ {

			ext_bin@0 {
				linux,phandle = <0x3d>;
				phandle = <0x3d>;
				samsung,area = <0x01>;
				samsung,name = "rtdsp.bin";
				samsung,offset = "\0P ";
				status = "okay";
			};

			ext_bin@1 {
				linux,phandle = <0x3e>;
				phandle = <0x3e>;
				samsung,area = <0x01>;
				samsung,name = "AP_AUDIO_SLSI.bin";
				samsung,offset = <0x7f0000>;
				status = "okay";
			};

			ext_bin@2 {
				linux,phandle = <0x3f>;
				phandle = <0x3f>;
				samsung,area = <0x01>;
				samsung,name = "APBargeIn_AUDIO_SLSI.bin";
				samsung,offset = <0x7ec000>;
				status = "okay";
			};

			ext_bin@4 {
				linux,phandle = <0x40>;
				phandle = <0x40>;
				samsung,area = <0x01>;
				samsung,name = "rtdsp_param.bin";
				samsung,offset = "\0X ";
				status = "okay";
			};

			ext_bin@5 {
				linux,phandle = <0x41>;
				phandle = <0x41>;
				samsung,area = <0x01>;
				samsung,name = "APBiBF_AUDIO_SLSI.bin";
				samsung,offset = <0x7ef000>;
				status = "okay";
			};
		};
	};

	fragment@16 {
		target = <0xffffffff>;

		__overlay__ {
			#address-cells = <0x01>;
			#size-cells = <0x00>;
			status = "okay";

			rt5510@34 {
				#sound-dai-cells = <0x01>;
				compatible = "richtek,rt5510";
				linux,phandle = <0x05>;
				phandle = <0x05>;
				reg = <0x34>;
				status = "okay";
			};
		};
	};

	fragment@17 {
		target = <0xffffffff>;

		__overlay__ {
			#address-cells = <0x01>;
			#size-cells = <0x00>;
			status = "okay";

			rt5665@1b {
				#sound-dai-cells = <0x01>;
				compatible = "realtek,rt5665";
				imp_table = <0x00 0x0d 0x03 0x06 0x0e 0x19 0x01 0x06 0x1a 0x35 0x00 0x06 0x36 0x67 0x00 0x06 0x68 0xffff 0x00 0x06>;
				interrupt-parent = <0xffffffff>;
				interrupts = <0x02 0x00 0x00>;
				linux,phandle = <0x04>;
				phandle = <0x04>;
				pinctrl-0 = <0x06>;
				pinctrl-names = "default";
				realtek,dmic2-data-pin = <0x02>;
				realtek,in1-differential;
				realtek,in3-differential;
				realtek,in4-differential;
				realtek,jd-src = <0x02>;
				realtek,offset-comp = <0x78 0x90 0xb0 0xc0 0xf0 0x110 0x130 0x180 0x1e0 0x200 0x2a0 0x300 0x3a0 0x400 0x500 0x600>;
				realtek,offset-comp-r = <0x1a 0x1f 0x20 0x2a 0x30 0x40 0x50 0x60 0x6f 0x7f 0xa0 0xb0 0xcf 0x100 0x120 0x160>;
				realtek,regulator_1v8 = <0x07>;
				realtek,regulator_3v3 = <0x08>;
				realtek,rek-first-playback;
				realtek,sar-hs-type = <0x2bc>;
				realtek,sar-pb-vth0 = <0x64>;
				realtek,sar-pb-vth1 = <0x91>;
				realtek,sar-pb-vth2 = <0xfa>;
				realtek,sar-pb-vth3 = <0x244>;
				reg = <0x1b>;
			};
		};
	};

	fragment@18 {
		target = <0xffffffff>;

		__overlay__ {

			fuel-irq {
				linux,phandle = <0x0a>;
				phandle = <0x0a>;
				samsung,pin-drv = <0x00>;
				samsung,pin-function = <0x00>;
				samsung,pin-pud = <0x03>;
				samsung,pin-pud-pdn = <0x03>;
				samsung,pins = "gpm20-0";
			};
		};
	};

	fragment@19 {
		target = <0xffffffff>;

		__overlay__ {

			dc-irq {
				linux,phandle = <0x09>;
				phandle = <0x09>;
				samsung,pin-drv = <0x00>;
				samsung,pin-function = <0x0f>;
				samsung,pin-pud = <0x00>;
				samsung,pins = "gpa1-4";
			};
		};
	};

	fragment@2 {
		target = <0xffffffff>;

		__overlay__ {
			non_secure_mem_info = <0xdb900000 0x700000>;
			pinctrl-0 = <0xffffffff 0xffffffff 0xffffffff>;
			pinctrl-1;
			pinctrl-names = "default\0release";
			secure_mem_info = <0xe1900000 0x2000000>;

			fimc_is_dvfs {

				table0 {
					default_cam = <0xaae60>;
					default_hpg = <0x01>;
					default_int = <0x186a0>;
					default_int_cam = <0xa8750>;
					default_mif = <0x1fefc8>;
					desc = "dvfs table v0.0 for 64M/32M";
					dual_capture_cam = <0xa8750>;
					dual_capture_hpg = <0x01>;
					dual_capture_int = <0x186a0>;
					dual_capture_int_cam = <0xa6040>;
					dual_capture_mif = <0x1fefc8>;
					dual_preview_cam = <0xa8750>;
					dual_preview_hpg = <0x01>;
					dual_preview_int = <0x186a0>;
					dual_preview_int_cam = <0xa1220>;
					dual_preview_mif = <0x1fefc8>;
					dual_sync_capture_cam = <0xa8750>;
					dual_sync_capture_hpg = <0x01>;
					dual_sync_capture_int = <0x186a0>;
					dual_sync_capture_int_cam = <0xa6040>;
					dual_sync_capture_mif = <0x1fefc8>;
					dual_sync_preview_cam = <0xa8750>;
					dual_sync_preview_hpg = <0x01>;
					dual_sync_preview_int = <0x186a0>;
					dual_sync_preview_int_cam = <0xa6040>;
					dual_sync_preview_mif = <0x1fefc8>;
					dual_sync_preview_whd_cam = <0xa8750>;
					dual_sync_preview_whd_hpg = <0x01>;
					dual_sync_preview_whd_int = <0x186a0>;
					dual_sync_preview_whd_int_cam = <0xa6040>;
					dual_sync_preview_whd_mif = <0x1fefc8>;
					dual_sync_video_fhd_cam = <0xa8750>;
					dual_sync_video_fhd_capture_cam = <0xa8750>;
					dual_sync_video_fhd_capture_hpg = <0x01>;
					dual_sync_video_fhd_capture_int = <0x186a0>;
					dual_sync_video_fhd_capture_int_cam = <0xa3930>;
					dual_sync_video_fhd_capture_mif = <0x1e8c50>;
					dual_sync_video_fhd_hpg = <0x01>;
					dual_sync_video_fhd_int = <0x186a0>;
					dual_sync_video_fhd_int_cam = <0xa3930>;
					dual_sync_video_fhd_mif = <0x177bb8>;
					dual_sync_video_uhd_cam = <0xa8750>;
					dual_sync_video_uhd_capture_cam = <0xa8750>;
					dual_sync_video_uhd_capture_hpg = <0x01>;
					dual_sync_video_uhd_capture_int = <0x186a0>;
					dual_sync_video_uhd_capture_int_cam = <0xa6040>;
					dual_sync_video_uhd_capture_mif = <0x1e8c50>;
					dual_sync_video_uhd_hpg = <0x01>;
					dual_sync_video_uhd_int = <0x186a0>;
					dual_sync_video_uhd_int_cam = <0xa6040>;
					dual_sync_video_uhd_mif = <0x1e8c50>;
					dual_sync_whd_capture_cam = <0xa8750>;
					dual_sync_whd_capture_hpg = <0x01>;
					dual_sync_whd_capture_int = <0x186a0>;
					dual_sync_whd_capture_int_cam = <0xa6040>;
					dual_sync_whd_capture_mif = <0x1fefc8>;
					dual_video_fhd_cam = <0xa8750>;
					dual_video_fhd_capture_cam = <0xa8750>;
					dual_video_fhd_capture_hpg = <0x01>;
					dual_video_fhd_capture_int = <0x186a0>;
					dual_video_fhd_capture_int_cam = <0xa3930>;
					dual_video_fhd_capture_mif = <0x177bb8>;
					dual_video_fhd_hpg = <0x01>;
					dual_video_fhd_int = <0x186a0>;
					dual_video_fhd_int_cam = <0xa1220>;
					dual_video_fhd_mif = <0x14a140>;
					dual_video_uhd_cam = <0xa8750>;
					dual_video_uhd_capture_cam = <0xa8750>;
					dual_video_uhd_capture_hpg = <0x01>;
					dual_video_uhd_capture_int = <0x186a0>;
					dual_video_uhd_capture_int_cam = <0xa6040>;
					dual_video_uhd_capture_mif = <0x1b5fd0>;
					dual_video_uhd_hpg = <0x01>;
					dual_video_uhd_int = <0x186a0>;
					dual_video_uhd_int_cam = <0xa3930>;
					dual_video_uhd_mif = <0x177bb8>;
					ext_front_cam = <0xaae60>;
					ext_front_hpg = <0x01>;
					ext_front_int = <0x186a0>;
					ext_front_int_cam = <0xa8750>;
					ext_front_mif = <0x1fefc8>;
					ext_secure_cam = <0xaae60>;
					ext_secure_hpg = <0x01>;
					ext_secure_int = <0x186a0>;
					ext_secure_int_cam = <0xa8750>;
					ext_secure_mif = <0x1fefc8>;
					front_capture_cam = <0xa6040>;
					front_capture_hpg = <0x01>;
					front_capture_int = <0x186a0>;
					front_capture_int_cam = <0xa6040>;
					front_capture_mif = <0x1fefc8>;
					front_capture_remosaic_cam = <0xaae60>;
					front_capture_remosaic_hpg = <0x01>;
					front_capture_remosaic_int = <0x186a0>;
					front_capture_remosaic_int_cam = <0xa6040>;
					front_capture_remosaic_mif = <0x1fefc8>;
					front_preview_cam = <0xa6040>;
					front_preview_full_cam = <0xa6040>;
					front_preview_full_hpg = <0x01>;
					front_preview_full_int = <0x186a0>;
					front_preview_full_int_cam = <0xa6040>;
					front_preview_full_mif = <0x1b5fd0>;
					front_preview_hpg = <0x01>;
					front_preview_int = <0x186a0>;
					front_preview_int_cam = <0xa1220>;
					front_preview_mif = <0x14a140>;
					front_preview_remosaic_cam = <0xaae60>;
					front_preview_remosaic_hpg = <0x01>;
					front_preview_remosaic_int = <0x186a0>;
					front_preview_remosaic_int_cam = <0xa6040>;
					front_preview_remosaic_mif = <0x1fefc8>;
					front_video_cam = <0xa6040>;
					front_video_capture_cam = <0xa6040>;
					front_video_capture_hpg = <0x01>;
					front_video_capture_int = <0x186a0>;
					front_video_capture_int_cam = <0xa3930>;
					front_video_capture_mif = <0x1b5fd0>;
					front_video_high_speed_120fps_cam = <0xaae60>;
					front_video_high_speed_120fps_hpg = <0x01>;
					front_video_high_speed_120fps_int = <0xa2d78>;
					front_video_high_speed_120fps_int_cam = <0xa8750>;
					front_video_high_speed_120fps_mif = <0x1fefc8>;
					front_video_hpg = <0x01>;
					front_video_int = <0x186a0>;
					front_video_int_cam = <0xa1220>;
					front_video_mif = <0x14a140>;
					front_vt1_cam = <0xa6040>;
					front_vt1_hpg = <0x01>;
					front_vt1_int = <0x186a0>;
					front_vt1_int_cam = <0xa1220>;
					front_vt1_mif = <0xf78f0>;
					front_vt2_cam = <0xa6040>;
					front_vt2_hpg = <0x01>;
					front_vt2_int = <0x186a0>;
					front_vt2_int_cam = <0xa1220>;
					front_vt2_mif = <0xf78f0>;
					front_vt4_cam = <0xa6040>;
					front_vt4_hpg = <0x01>;
					front_vt4_int = <0x186a0>;
					front_vt4_int_cam = <0xa1220>;
					front_vt4_mif = <0xf78f0>;
					max_cam = <0xaae60>;
					max_hpg = <0x01>;
					max_int = <0xa2d78>;
					max_int_cam = <0xa8750>;
					max_mif = <0x1fefc8>;
					preview_high_speed_fps_cam = <0xa8750>;
					preview_high_speed_fps_hpg = <0x01>;
					preview_high_speed_fps_int = <0x186a0>;
					preview_high_speed_fps_int_cam = <0xa6040>;
					preview_high_speed_fps_mif = <0x1fefc8>;
					rear2_capture_cam = <0xa3930>;
					rear2_capture_hpg = <0x01>;
					rear2_capture_int = <0x186a0>;
					rear2_capture_int_cam = <0xa1220>;
					rear2_capture_mif = <0x177bb8>;
					rear2_preview_fhd_cam = <0xa3930>;
					rear2_preview_fhd_hpg = <0x01>;
					rear2_preview_fhd_int = <0x186a0>;
					rear2_preview_fhd_int_cam = <0xa1220>;
					rear2_preview_fhd_mif = <0x14a140>;
					rear3_capture_cam = <0xa6040>;
					rear3_capture_hpg = <0x01>;
					rear3_capture_int = <0x186a0>;
					rear3_capture_int_cam = <0xa3930>;
					rear3_capture_mif = <0x1b5fd0>;
					rear3_preview_cam = <0xa6040>;
					rear3_preview_hpg = <0x01>;
					rear3_preview_int = <0x186a0>;
					rear3_preview_int_cam = <0xa3930>;
					rear3_preview_mif = <0x177bb8>;
					rear3_video_cam = <0xa6040>;
					rear3_video_capture_cam = <0xa6040>;
					rear3_video_capture_hpg = <0x01>;
					rear3_video_capture_int = <0x186a0>;
					rear3_video_capture_int_cam = <0xa3930>;
					rear3_video_capture_mif = <0x1b5fd0>;
					rear3_video_hpg = <0x01>;
					rear3_video_int = <0x186a0>;
					rear3_video_int_cam = <0xa3930>;
					rear3_video_mif = <0x177bb8>;
					rear4_capture_cam = <0xa3930>;
					rear4_capture_hpg = <0x01>;
					rear4_capture_int = <0x186a0>;
					rear4_capture_int_cam = <0xa1220>;
					rear4_capture_mif = <0xf78f0>;
					rear4_preview_cam = <0xa3930>;
					rear4_preview_hpg = <0x01>;
					rear4_preview_int = <0x186a0>;
					rear4_preview_int_cam = <0xa1220>;
					rear4_preview_mif = <0xf78f0>;
					rear_capture_cam = <0xa8750>;
					rear_capture_hpg = <0x01>;
					rear_capture_int = <0x186a0>;
					rear_capture_int_cam = <0xa8750>;
					rear_capture_mif = <0x1fefc8>;
					rear_capture_remosaic_cam = <0xaae60>;
					rear_capture_remosaic_hpg = <0x01>;
					rear_capture_remosaic_int = <0x186a0>;
					rear_capture_remosaic_int_cam = <0xa8750>;
					rear_capture_remosaic_mif = <0x1fefc8>;
					rear_preview_fhd_cam = <0xa8750>;
					rear_preview_fhd_hpg = <0x01>;
					rear_preview_fhd_int = <0x186a0>;
					rear_preview_fhd_int_cam = <0xa6040>;
					rear_preview_fhd_mif = <0x1fefc8>;
					rear_preview_full_cam = <0xa8750>;
					rear_preview_full_hpg = <0x01>;
					rear_preview_full_int = <0x186a0>;
					rear_preview_full_int_cam = <0xa6040>;
					rear_preview_full_mif = <0x1fefc8>;
					rear_preview_hd_cam = <0xa8750>;
					rear_preview_hd_hpg = <0x01>;
					rear_preview_hd_int = <0x186a0>;
					rear_preview_hd_int_cam = <0xa3930>;
					rear_preview_hd_mif = <0x1fefc8>;
					rear_preview_remosaic_cam = <0xaae60>;
					rear_preview_remosaic_hpg = <0x01>;
					rear_preview_remosaic_int = <0x186a0>;
					rear_preview_remosaic_int_cam = <0xa8750>;
					rear_preview_remosaic_mif = <0x1fefc8>;
					rear_preview_uhd_cam = <0xa8750>;
					rear_preview_uhd_hpg = <0x01>;
					rear_preview_uhd_int = <0x82208>;
					rear_preview_uhd_int_cam = <0xa6040>;
					rear_preview_uhd_mif = <0x1fefc8>;
					rear_video_fhd_cam = <0xa8750>;
					rear_video_fhd_capture_cam = <0xa8750>;
					rear_video_fhd_capture_hpg = <0x01>;
					rear_video_fhd_capture_int = <0x186a0>;
					rear_video_fhd_capture_int_cam = <0xa6040>;
					rear_video_fhd_capture_mif = <0x1b5fd0>;
					rear_video_fhd_hpg = <0x01>;
					rear_video_fhd_int = <0x186a0>;
					rear_video_fhd_int_cam = <0xa3930>;
					rear_video_fhd_mif = <0x177bb8>;
					rear_video_hd_cam = <0xa8750>;
					rear_video_hd_capture_cam = <0xa8750>;
					rear_video_hd_capture_hpg = <0x01>;
					rear_video_hd_capture_int = <0x186a0>;
					rear_video_hd_capture_int_cam = <0xa3930>;
					rear_video_hd_capture_mif = <0x177bb8>;
					rear_video_hd_hpg = <0x01>;
					rear_video_hd_int = <0x186a0>;
					rear_video_hd_int_cam = <0xa6040>;
					rear_video_hd_mif = <0x177bb8>;
					rear_video_uhd_cam = <0xa8750>;
					rear_video_uhd_capture_cam = <0xa8750>;
					rear_video_uhd_capture_hpg = <0x01>;
					rear_video_uhd_capture_int = <0x186a0>;
					rear_video_uhd_capture_int_cam = <0xa6040>;
					rear_video_uhd_capture_mif = <0x1b5fd0>;
					rear_video_uhd_hpg = <0x01>;
					rear_video_uhd_int = <0x186a0>;
					rear_video_uhd_int_cam = <0xa3930>;
					rear_video_uhd_mif = <0x177bb8>;
					video_high_speed_120fps_cam = <0xa8750>;
					video_high_speed_120fps_hpg = <0x01>;
					video_high_speed_120fps_int = <0x186a0>;
					video_high_speed_120fps_int_cam = <0xa6040>;
					video_high_speed_120fps_mif = <0x1fefc8>;
					video_high_speed_240fps_cam = <0xa8750>;
					video_high_speed_240fps_hpg = <0x08>;
					video_high_speed_240fps_int = <0x186a0>;
					video_high_speed_240fps_int_cam = <0xa6040>;
					video_high_speed_240fps_mif = <0x1fefc8>;
					video_high_speed_480fps_cam = <0xaae60>;
					video_high_speed_480fps_hpg = <0x01>;
					video_high_speed_480fps_int = <0xa2d78>;
					video_high_speed_480fps_int_cam = <0xa8750>;
					video_high_speed_480fps_mif = <0x1fefc8>;
					video_high_speed_60fps_cam = <0xa8750>;
					video_high_speed_60fps_capture_cam = <0xaae60>;
					video_high_speed_60fps_capture_hpg = <0x01>;
					video_high_speed_60fps_capture_int = <0x186a0>;
					video_high_speed_60fps_capture_int_cam = <0xa8750>;
					video_high_speed_60fps_capture_mif = <0x1fefc8>;
					video_high_speed_60fps_hpg = <0x01>;
					video_high_speed_60fps_int = <0x186a0>;
					video_high_speed_60fps_int_cam = <0xa6040>;
					video_high_speed_60fps_mif = <0x1fefc8>;
				};
			};

			vender {
				check_sensor_vendor;
				front_sensor_id = <0x79>;
				max_camera_num = <0x05>;
				max_supported_camera = <0x06>;
				need_i2c_config;
				rear2_sensor_id = <0xd2>;
				rear3_sensor_id = <0x3b>;
				rear4_sensor_id = <0xd2>;
				rear_sensor_id = <0x7c>;
				supported_cameraId = <0x00 0x03 0x17 0x32 0x34 0x36>;
				use_module_check;

				camera_info0 {
					cal_memory = <0x02>;
					companion = <0x00>;
					core_voltage = <0x00>;
					dual_open = <0x00>;
					isp = <0x00>;
					ois = <0x00>;
					position = <0x00>;
					read_version = <0x00>;
					upgrade = <0x00>;
					valid = <0x01>;
				};

				camera_info1 {
					cal_memory = <0x02>;
					companion = <0x00>;
					core_voltage = <0x00>;
					dual_open = <0x00>;
					isp = <0x00>;
					ois = <0x00>;
					position = <0x01>;
					read_version = <0x00>;
					upgrade = <0x00>;
					valid = <0x01>;
				};

				camera_info2 {
					cal_memory = <0x03>;
					companion = <0x00>;
					core_voltage = <0x00>;
					dual_open = <0x01>;
					isp = <0x00>;
					ois = <0x00>;
					position = <0x02>;
					read_version = <0x00>;
					upgrade = <0x00>;
					valid = <0x01>;
				};

				camera_info3 {
					cal_memory = <0x02>;
					companion = <0x00>;
					core_voltage = <0x00>;
					dual_open = <0x00>;
					isp = <0x00>;
					ois = <0x00>;
					position = <0x04>;
					read_version = <0x00>;
					upgrade = <0x00>;
					valid = <0x01>;
				};

				camera_info4 {
					cal_memory = <0x02>;
					companion = <0x00>;
					core_voltage = <0x00>;
					dual_open = <0x00>;
					isp = <0x00>;
					ois = <0x00>;
					position = <0x06>;
					read_version = <0x00>;
					upgrade = <0x00>;
					valid = <0x01>;
				};
			};
		};
	};

	fragment@20 {
		target = <0xffffffff>;

		__overlay__ {
			status = "okay";

			sm5440@63 {
				compatible = "siliconmitus,sm5440";
				pinctrl-0 = <0x09>;
				pinctrl-names = "default";
				reg = <0x63>;
				sm5440,PPS_LR = <0x4baf0>;
				sm5440,RPARA = <0x249f0>;
				sm5440,RPCM = <0x6b6c>;
				sm5440,RSNS = <0x00>;
				sm5440,cc_gl_offset = <0x12c>;
				sm5440,ci_gl_offset = <0x96>;
				sm5440,cv_gl_offset = <0x00>;
				sm5440,dc_min_vbat = <0xdac>;
				sm5440,freq = <0x44c>;
				sm5440,irq-gpio = <0xffffffff 0x04 0x00>;
				sm5440,ta_min_curr = <0x3e8>;
				sm5440,ta_min_voltage = <0x2008>;
			};
		};
	};

	fragment@21 {
		target = <0xffffffff>;

		__overlay__ {

			s2mu106-fuelgauge@3B {
				compatible = "samsung,s2mu106-fuelgauge";
				fuelgauge,capacity_calculation_type = <0x1c>;
				fuelgauge,capacity_full = <0x1770>;
				fuelgauge,capacity_max = <0x3de>;
				fuelgauge,capacity_max_margin = <0xc8>;
				fuelgauge,capacity_min = <0x00>;
				fuelgauge,fg_log_enable = <0x01>;
				fuelgauge,fuel_alert_soc = <0x01>;
				fuelgauge,fuel_alert_vol = <0xce4>;
				fuelgauge,fuel_int = <0xffffffff 0x00 0x00>;
				fuelgauge,i_socr_coeff = <0x50>;
				fuelgauge,low_t_compen_coeff = <0xb4>;
				fuelgauge,low_temp_limit = <0x64>;
				fuelgauge,low_voltage_limit_lowtemp = <0xbb8>;
				fuelgauge,sw_vbat_l_recovery_vol = <0xd89>;
				fuelgauge,type_str = "SDI";
				pinctrl-0 = <0x0a>;
				pinctrl-names = "default";
				reg = <0x3b>;
				status = "okay";
			};
		};
	};

	fragment@22 {
		target = <0xffffffff>;

		__overlay__ {
			parts = "vbmeta,boot,system,vendor,product,odm,prism,optics,vbmeta_samsung,recovery,dtbo,keystorage";
			status = "okay";
		};
	};

	fragment@23 {
		target = <0xffffffff>;

		__overlay__ {
			status = "disabled";
		};
	};

	fragment@24 {
		target = <0xffffffff>;

		__overlay__ {
			status = "okay";

			dwc3 {
				dr_mode = "otg";
				maximum-speed = "high-speed";
			};
		};
	};

	fragment@25 {
		target = <0xffffffff>;

		__overlay__ {
			dr_mode = "otg";
			ldo-names = "vdd_ldo12\0vdd_ldo13\0vdd_ldo14";
			maximum-speed = "high-speed";
		};
	};

	fragment@26 {
		target = <0xffffffff>;

		__overlay__ {
			hs_tune_param = <0x15>;
			status = "okay";
			usb3phy-isolation = <0x01>;
		};
	};

	fragment@27 {
		target = <0xffffffff>;

		__overlay__ {
			hs_tune_param = <0x16>;
			ss_tune_param = <0x17>;
			status = "okay";
			usb3phy-isolation = <0x01>;
		};
	};

	fragment@28 {
		target = <0xffffffff>;

		__overlay__ {
			samsung,uart-logging;
			status = "okay";
		};
	};

	fragment@29 {
		target = <0xffffffff>;

		__overlay__ {

			attn-input {
				linux,phandle = <0x12>;
				phandle = <0x12>;
				samsung,pin-function = <0x00>;
				samsung,pin-pud = <0x01>;
				samsung,pins = "gpa0-0";
			};

			attn-irq {
				linux,phandle = <0x11>;
				phandle = <0x11>;
				samsung,pin-drv = <0x00>;
				samsung,pin-function = <0x0f>;
				samsung,pin-pud = <0x00>;
				samsung,pins = "gpa0-0";
			};

			codec_irq {
				linux,phandle = <0x06>;
				phandle = <0x06>;
				samsung,pin-function = <0x0f>;
				samsung,pin-pud = <0x00>;
				samsung,pins = "gpa1-2";
			};

			dwmmc2_cd_ext_irq {
				linux,phandle = <0x13>;
				phandle = <0x13>;
				samsung,pin-drv = <0x03>;
				samsung,pin-function = <0x0f>;
				samsung,pin-pud = <0x00>;
				samsung,pins = "gpa2-4";
			};

			if-pmic-irq {
				linux,phandle = <0x19>;
				phandle = <0x19>;
				samsung,pin-drv = <0x00>;
				samsung,pin-function = <0x00>;
				samsung,pin-pud = <0x00>;
				samsung,pins = "gpa2-2";
			};

			key-power {
				linux,phandle = <0x10>;
				phandle = <0x10>;
				samsung,pin-drv = <0x00>;
				samsung,pin-function = <0x0f>;
				samsung,pin-pud = <0x00>;
				samsung,pins = "gpa1-7";
			};

			key-voldown {
				linux,phandle = <0x0e>;
				phandle = <0x0e>;
				samsung,pin-drv = <0x00>;
				samsung,pin-function = <0x0f>;
				samsung,pin-pud = <0x00>;
				samsung,pins = "gpa1-6";
			};

			key-volup {
				linux,phandle = <0x0f>;
				phandle = <0x0f>;
				samsung,pin-drv = <0x00>;
				samsung,pin-function = <0x0f>;
				samsung,pin-pud = <0x00>;
				samsung,pins = "gpa1-5";
			};

			motor-en {
				linux,phandle = <0x1a>;
				phandle = <0x1a>;
				samsung,pin-con-pdn = <0x03>;
				samsung,pin-function = <0x01>;
				samsung,pin-pud = <0x00>;
				samsung,pin-pud-pdn = <0x00>;
				samsung,pin-val = <0x00>;
				samsung,pins = "gpa2-1";
			};

			pmic-irq {
				linux,phandle = <0x0b>;
				phandle = <0x0b>;
				samsung,pin-drv = <0x03>;
				samsung,pin-pud = <0x03>;
				samsung,pins = "gpa2-0";
			};

			sub_detect_conn_setting {
				linux,phandle = <0x14>;
				phandle = <0x14>;
				samsung,pin-drv = <0x00>;
				samsung,pin-function = <0x0f>;
				samsung,pin-pud = <0x00>;
				samsung,pins = "gpa0-2";
			};

			usbpd-irq {
				linux,phandle = <0x18>;
				phandle = <0x18>;
				samsung,pin-drv = <0x00>;
				samsung,pin-function = <0x0f>;
				samsung,pin-pud = <0x00>;
				samsung,pins = "gpa2-3";
			};
		};
	};

	fragment@3 {
		target = <0xffffffff>;

		__overlay__ {
			#address-cells = <0x01>;
			#size-cells = <0x00>;
			clock-frequency = <0xf4240>;
			gpios = <0xffffffff 0x00 0x00 0xffffffff 0x01 0x00>;
			pinctrl-0 = <0xffffffff>;
			pinctrl-1 = <0xffffffff>;
			pinctrl-2 = <0xffffffff>;
			pinctrl-names = "default\0on_i2c\0off_i2c";
			samsung,fast-plus-mode;
			samsung,reset-before-trans;
			status = "okay";

			fimc-is-imx616@34 {
				compatible = "samsung,exynos5-fimc-is-cis-imx616";
				id = <0x01>;
				reg = <0x1a>;
				sensor_f_number = <0xdc>;
				setfile = "setB";
				use_3hdr;
				use_initial_ae;
			};
		};
	};

	fragment@30 {
		target = <0xffffffff>;

		__overlay__ {

			pm-wrsti {
				linux,phandle = <0x0c>;
				phandle = <0x0c>;
				samsung,pin-con-pdn = <0x03>;
				samsung,pins = "gpg0-7";
			};
		};
	};

	fragment@31 {
		target = <0xffffffff>;

		__overlay__ {
			exynos,block-type = "sda";
			exynos,fips-block_offset = <0x05>;
		};
	};

	fragment@32 {
		target = <0xffffffff>;

		__overlay__ {
			status = "disabled";
		};
	};

	fragment@33 {
		target = <0xffffffff>;

		__overlay__ {
			status = "disabled";
		};
	};

	fragment@34 {
		target = <0xffffffff>;

		__overlay__ {
			status = "okay";
			usi_v2_mode = "spi";
		};
	};

	fragment@35 {
		target = <0xffffffff>;

		__overlay__ {
			status = "disabled";
		};
	};

	fragment@36 {
		target = <0xffffffff>;

		__overlay__ {
			status = "disabled";
		};
	};

	fragment@37 {
		target = <0xffffffff>;

		__overlay__ {
			status = "okay";
			usi_v2_mode = "i2c";
		};
	};

	fragment@38 {
		target = <0xffffffff>;

		__overlay__ {
			status = "okay";
			usi_v2_mode = "i2c";
		};
	};

	fragment@39 {
		target = <0xffffffff>;

		__overlay__ {
			status = "disabled";
		};
	};

	fragment@4 {
		target = <0xffffffff>;

		__overlay__ {
			#address-cells = <0x01>;
			#size-cells = <0x00>;
			clock-frequency = <0xf4240>;
			gpios = <0xffffffff 0x02 0x00 0xffffffff 0x03 0x00>;
			pinctrl-0 = <0xffffffff>;
			pinctrl-1 = <0xffffffff>;
			pinctrl-2 = <0xffffffff>;
			pinctrl-names = "default\0on_i2c\0off_i2c";
			samsung,fast-plus-mode;
			samsung,reset-before-trans;
			status = "okay";

			fimc-is-imx682@34 {
				compatible = "samsung,exynos5-fimc-is-cis-imx682";
				id = <0x00>;
				reg = <0x1a>;
				sensor_f_number = <0xb4>;
				setfile = "setB";
			};
		};
	};

	fragment@40 {
		target = <0xffffffff>;

		__overlay__ {
			status = "okay";
			usi_v2_mode = "i2c";
		};
	};

	fragment@41 {
		target = <0xffffffff>;

		__overlay__ {
			status = "disabled";
		};
	};

	fragment@42 {
		target = <0xffffffff>;

		__overlay__ {
			status = "okay";
			usi_v2_mode = "spi";
		};
	};

	fragment@43 {
		target = <0xffffffff>;

		__overlay__ {
			status = "disabled";
		};
	};

	fragment@44 {
		target = <0xffffffff>;

		__overlay__ {
			status = "okay";
			usi_v2_mode = "i2c";
		};
	};

	fragment@45 {
		target = <0xffffffff>;

		__overlay__ {
			status = "disabled";
		};
	};

	fragment@46 {
		target = <0xffffffff>;

		__overlay__ {
			status = "okay";
			usi_v2_mode = "spi";
		};
	};

	fragment@47 {
		target = <0xffffffff>;

		__overlay__ {
			bootargs_ext = "root=/dev/ram0 androidboot.boot_devices=13520000.ufs";
		};
	};

	fragment@48 {
		target = <0xffffffff>;

		__overlay__ {
			#address-cells = <0x00>;
			#size-cells = <0x00>;
			i2c-gpio,delay-us = <0x01>;
			samsung,fix-doxfer-return;
			samsung,glitch-filter;
			samsung,i2c-max-bus-freq = <0x61a80>;
			status = "okay";

			usbpd-s2mu106@3C {
				compatible = "s2mu106-usbpd";
				pinctrl-0 = <0x18>;
				pinctrl-names = "default";
				reg = <0x3c>;
				status = "okay";
				usbpd,usbpd_int = <0xffffffff 0x03 0x00>;
			};
		};
	};

	fragment@49 {
		target = <0xffffffff>;

		__overlay__ {
			#address-cells = <0x01>;
			#size-cells = <0x00>;
			samsung,i2c-max-bus-freq = <0x61a80>;
			status = "okay";

			s2mu106@3A {

				s2mu106-haptic {
					compatible = "sec,s2mu106-haptic";
					haptic,motor_en = <0xffffffff 0x01 0x00>;
					haptic,motor_type = "COINDC";
					haptic,operation_mode = <0x01>;
					pinctrl-0 = <0x1a>;
					pinctrl-names = "default";
					status = "okay";
				};
			};

			s2mu106@3D {
				compatible = "samsung,s2mu106mfd";
				pinctrl-0 = <0x19>;
				pinctrl-names = "default";
				reg = <0x3d>;
				s2mu106,irq-gpio = <0xffffffff 0x02 0x01>;
				s2mu106,wakeup;
				status = "okay";
			};
		};
	};

	fragment@5 {
		target = <0xffffffff>;

		__overlay__ {
			#address-cells = <0x01>;
			#size-cells = <0x00>;
			clock-frequency = <0x61a80>;
			gpios = <0xffffffff 0x04 0x00 0xffffffff 0x05 0x00>;
			pinctrl-0 = <0xffffffff>;
			pinctrl-1 = <0xffffffff>;
			pinctrl-2 = <0xffffffff>;
			pinctrl-names = "default\0on_i2c\0off_i2c";
			samsung,reset-before-trans;
			status = "okay";

			fimc-is-gc5035@6E {
				compatible = "samsung,exynos5-fimc-is-cis-gc5035";
				id = <0x02>;
				reg = <0x37>;
				rom_position = <0x02>;
				sensor_f_number = <0xf0>;
				setfile = "setB";
				use_different_isp_module;
				use_initial_ae;
				use_sensor_otp;
			};
		};
	};

	fragment@50 {
		target = <0xffffffff>;

		__overlay__ {
			#address-cells = <0x01>;
			#size-cells = <0x00>;
			status = "okay";

			s2mpb03@56 {
				compatible = "samsung,s2mpb03pmic";
				reg = <0x56>;
				s2mpb03,wakeup;

				regulators {

					s2mpb03-ldo1 {
						linux,phandle = <0x66>;
						phandle = <0x66>;
						regulator-max-microvolt = <0x100590>;
						regulator-min-microvolt = <0x100590>;
						regulator-name = "CAM_VLDO1";
					};

					s2mpb03-ldo2 {
						linux,phandle = <0x67>;
						phandle = <0x67>;
						regulator-max-microvolt = <0x10c8e0>;
						regulator-min-microvolt = <0x10c8e0>;
						regulator-name = "CAM_VLDO2";
					};

					s2mpb03-ldo3 {
						linux,phandle = <0x68>;
						phandle = <0x68>;
						regulator-max-microvolt = <0x1b7740>;
						regulator-min-microvolt = <0x1b7740>;
						regulator-name = "CAM_VLDO3";
					};

					s2mpb03-ldo4 {
						linux,phandle = <0x69>;
						phandle = <0x69>;
						regulator-max-microvolt = <0x124f80>;
						regulator-min-microvolt = <0x124f80>;
						regulator-name = "CAM_VLDO4";
					};

					s2mpb03-ldo5 {
						linux,phandle = <0x6a>;
						phandle = <0x6a>;
						regulator-max-microvolt = <0x2c4020>;
						regulator-min-microvolt = <0x2c4020>;
						regulator-name = "CAM_VLDO5";
					};

					s2mpb03-ldo6 {
						linux,phandle = <0x6b>;
						phandle = <0x6b>;
						regulator-max-microvolt = <0x2c4020>;
						regulator-min-microvolt = <0x2c4020>;
						regulator-name = "CAM_VLDO6";
					};

					s2mpb03-ldo7 {
						linux,phandle = <0x6c>;
						phandle = <0x6c>;
						regulator-max-microvolt = <0x2ab980>;
						regulator-min-microvolt = <0x2ab980>;
						regulator-name = "CAM_VLDO7";
					};
				};
			};
		};
	};

	fragment@51 {
		target = <0xffffffff>;

		__overlay__ {

			camera_contig {
				compatible = "exynos9820-ion";
				ion,heapname = "camera_heap";
				ion,protection_id = <0x0a>;
				ion,secure;
				reg = <0x00 0xdb900000 0x700000>;
			};

			secure_camera {
				compatible = "exynos9820-ion";
				ion,alignment = <0x10000>;
				ion,heapname = "secure_camera_heap";
				ion,protection_id = <0x0b>;
				ion,secure;
				reg = <0x00 0xe1900000 0x2000000>;
			};
		};
	};

	fragment@52 {
		target = <0xffffffff>;

		__overlay__ {
			chub-irq-pin;
			chub-irq-pin-len = <0x00>;
			clock-names = "chub_bus\0cmgp_i2c";
			clocks = <0xffffffff 0x258 0xffffffff 0x7d>;
			os-type = "sensorhub/shub_ramen_m31s.fw";
			sensor-ldo-en = <0xffffffff 0x00 0x01>;
			ssp-acc-position = <0x03>;
			ssp-brightness-array = <0x0f 0x28 0x32 0x4d 0xff>;
			ssp-brightness-array-len = <0x05>;
			ssp-light-cam-br = <0x3c 0x3c>;
			ssp-light-cam-lux = <0x64 0xc8>;
			ssp-light-position = <0x34 0x05 0x03 0x1c 0x01 0x08>;
			ssp-mag-array = [03 e1 ff f2 00 13 ff d7 03 b9 ff f5 ff e6 ff fa 04 09 00 00 00 00 00 00 00 00];
			ssp-mag-position = <0x03>;
		};
	};

	fragment@53 {
		target = <0xffffffff>;

		__overlay__ {

			nfc_clk_req {
				linux,phandle = <0x1d>;
				phandle = <0x1d>;
				samsung,pin-pud = <0x01>;
				samsung,pins = "gpa2-6";
			};

			nfc_clk_req_nc {
				linux,phandle = <0x21>;
				phandle = <0x21>;
				samsung,pin-function = <0x00>;
				samsung,pin-pud = <0x01>;
				samsung,pins = "gpa2-6";
			};

			xclkout1_nc {
				linux,phandle = <0x22>;
				phandle = <0x22>;
				samsung,pin-function = <0x00>;
				samsung,pin-pud = <0x01>;
				samsung,pins = "gpq0-0";
			};
		};
	};

	fragment@54 {
		target = <0xffffffff>;

		__overlay__ {

			nfc-check {
				linux,phandle = <0x1e>;
				phandle = <0x1e>;
				samsung,pin-function = <0x00>;
				samsung,pin-pud = <0x00>;
				samsung,pin-pud-pdn = <0x00>;
				samsung,pins = "gpg0-3";
			};

			nfc_en {
				linux,phandle = <0x1b>;
				phandle = <0x1b>;
				samsung,pin-con-pdn = <0x03>;
				samsung,pin-drv = <0x00>;
				samsung,pin-function = <0x00>;
				samsung,pin-pud = <0x00>;
				samsung,pin-pud-pdn = <0x00>;
				samsung,pins = "gpg0-0";
			};

			nfc_en_nc {
				linux,phandle = <0x1f>;
				phandle = <0x1f>;
				samsung,pin-con-pdn = <0x02>;
				samsung,pin-function = <0x00>;
				samsung,pin-pud = <0x01>;
				samsung,pin-pud-pdn = <0x01>;
				samsung,pins = "gpg0-0";
			};

			nfc_firm {
				linux,phandle = <0x1c>;
				phandle = <0x1c>;
				samsung,pin-con-pdn = <0x03>;
				samsung,pin-function = <0x01>;
				samsung,pin-pud = <0x00>;
				samsung,pin-pud-pdn = <0x00>;
				samsung,pin-val = <0x00>;
				samsung,pins = "gpg1-0";
			};

			nfc_firm_nc {
				linux,phandle = <0x20>;
				phandle = <0x20>;
				samsung,pin-con-pdn = <0x02>;
				samsung,pin-function = <0x00>;
				samsung,pin-pud = <0x01>;
				samsung,pin-pud-pdn = <0x01>;
				samsung,pins = "gpg1-0";
			};
		};
	};

	fragment@55 {
		target = <0xffffffff>;

		__overlay__ {
			#address-cells = <0x01>;
			#size-cells = <0x00>;
			clock-frequency = <0x61a80>;
			samsung,reset-before-trans;
			status = "okay";

			sec-nfc@27 {
				clock-names = "oscclk_nfc";
				clocks = <0xffffffff 0x320>;
				compatible = "sec-nfc";
				interrupt-parent = <0xffffffff>;
				interrupts = <0x00 0x00 0x00>;
				pinctrl-0 = <0x1b 0x1c 0xffffffff 0x1d 0x1e>;
				pinctrl-1 = <0x1f 0x20 0x21 0x22>;
				pinctrl-names = "default\0nfc_nc";
				reg = <0x27>;
				sec-nfc,check_nfc = <0xffffffff 0x03 0x00>;
				sec-nfc,clk_req-gpio = <0xffffffff 0x06 0x00>;
				sec-nfc,clk_use = <0x02>;
				sec-nfc,firm-gpio = <0xffffffff 0x00 0x01>;
				sec-nfc,irq-gpio = <0xffffffff 0x00 0x00>;
				sec-nfc,ldo_control;
				sec-nfc,nfc_ap_clk;
				sec-nfc,nfc_pvdd = "VDD_NFC_1P8";
				sec-nfc,ven-gpio = <0xffffffff 0x00 0x00>;
			};
		};
	};

	fragment@56 {
		target = <0xffffffff>;

		__overlay__ {
			pinctrl-0 = <0x23>;
			pinctrl-names = "default";

			initial-state {
				linux,phandle = <0x23>;
				phandle = <0x23>;

				gpa0-6 {
					samsung,pin-function = <0x00>;
					samsung,pin-pud = <0x01>;
					samsung,pins = "gpa0-6";
				};

				gpa2-5 {
					samsung,pin-function = <0x00>;
					samsung,pin-pud = <0x01>;
					samsung,pins = "gpa2-5";
				};
			};
		};
	};

	fragment@57 {
		target = <0xffffffff>;

		__overlay__ {
			pinctrl-0 = <0x24>;
			pinctrl-1 = <0x25>;
			pinctrl-names = "default\0sleep";

			initial-state {
				linux,phandle = <0x24>;
				phandle = <0x24>;

				gpm21-0 {
					samsung,pin-drv = <0x00>;
					samsung,pin-function = <0x01>;
					samsung,pin-pud = <0x00>;
					samsung,pins = "gpm21-0";
				};
			};

			sleep-state {
				linux,phandle = <0x25>;
				phandle = <0x25>;

				gpm12-0 {
					samsung,pin-con-pdn = <0x00>;
					samsung,pin-pud-pdn = <0x01>;
					samsung,pins = "gpm12-0";
				};

				gpm13-0 {
					samsung,pin-con-pdn = <0x00>;
					samsung,pin-pud-pdn = <0x01>;
					samsung,pins = "gpm13-0";
				};

				gpm14-0 {
					samsung,pin-con-pdn = <0x00>;
					samsung,pin-pud-pdn = <0x01>;
					samsung,pins = "gpm14-0";
				};

				gpm21-0 {
					samsung,pin-con-pdn = <0x03>;
					samsung,pin-pud-pdn = <0x00>;
					samsung,pins = "gpm21-0";
				};
			};
		};
	};

	fragment@58 {
		target = <0xffffffff>;

		__overlay__ {
			pinctrl-0 = <0x26>;
			pinctrl-names = "sleep";

			sleep-state {
				linux,phandle = <0x26>;
				phandle = <0x26>;

				gpb2-0 {
					samsung,pin-con-pdn = <0x02>;
					samsung,pin-pud-pdn = <0x01>;
					samsung,pins = "gpb2-0";
				};

				gpb2-1 {
					samsung,pin-con-pdn = <0x02>;
					samsung,pin-pud-pdn = <0x01>;
					samsung,pins = "gpb2-1";
				};

				gpb2-2 {
					samsung,pin-con-pdn = <0x02>;
					samsung,pin-pud-pdn = <0x01>;
					samsung,pins = "gpb2-2";
				};

				gpb2-3 {
					samsung,pin-con-pdn = <0x02>;
					samsung,pin-pud-pdn = <0x01>;
					samsung,pins = "gpb2-3";
				};

				gpb2-4 {
					samsung,pin-con-pdn = <0x02>;
					samsung,pin-pud-pdn = <0x01>;
					samsung,pins = "gpb2-4";
				};
			};
		};
	};

	fragment@59 {
		target = <0xffffffff>;

		__overlay__ {
			pinctrl-0 = <0x27>;
			pinctrl-1 = <0x28>;
			pinctrl-names = "default\0sleep";

			initial-state {
				linux,phandle = <0x27>;
				phandle = <0x27>;

				gpc2-4 {
					samsung,pin-function = <0x00>;
					samsung,pin-pud = <0x01>;
					samsung,pins = "gpc2-4";
				};

				gpg0-1 {
					samsung,pin-function = <0x00>;
					samsung,pin-pud = <0x01>;
					samsung,pins = "gpg0-1";
				};

				gpg0-7 {
					samsung,pin-function = <0x00>;
					samsung,pin-pud = <0x01>;
					samsung,pins = "gpg0-7";
				};

				gpg1-4 {
					samsung,pin-function = <0x00>;
					samsung,pin-pud = <0x01>;
					samsung,pins = "gpg1-4";
				};

				gpg1-5 {
					samsung,pin-function = <0x00>;
					samsung,pin-pud = <0x01>;
					samsung,pins = "gpg1-5";
				};

				gpg2-0 {
					samsung,pin-function = <0x00>;
					samsung,pin-pud = <0x01>;
					samsung,pins = "gpg2-0";
				};

				gpg2-2 {
					samsung,pin-function = <0x00>;
					samsung,pin-pud = <0x01>;
					samsung,pins = "gpg2-2";
				};

				gpg2-3 {
					samsung,pin-function = <0x00>;
					samsung,pin-pud = <0x01>;
					samsung,pins = "gpg2-3";
				};

				gpg2-5 {
					samsung,pin-function = <0x00>;
					samsung,pin-pud = <0x01>;
					samsung,pins = "gpg2-5";
				};

				gpg2-6 {
					samsung,pin-function = <0x00>;
					samsung,pin-pud = <0x01>;
					samsung,pins = "gpg2-6";
				};

				gpg3-1 {
					samsung,pin-drv = <0x00>;
					samsung,pin-function = <0x01>;
					samsung,pin-pud = <0x00>;
					samsung,pin-val = <0x01>;
					samsung,pins = "gpg3-1";
				};

				gpg3-2 {
					samsung,pin-function = <0x00>;
					samsung,pin-pud = <0x00>;
					samsung,pins = "gpg3-2";
				};

				gpg3-3 {
					samsung,pin-function = <0x00>;
					samsung,pin-pud = <0x00>;
					samsung,pins = "gpg3-3";
				};

				gpg3-4 {
					samsung,pin-function = <0x00>;
					samsung,pin-pud = <0x01>;
					samsung,pins = "gpg3-4";
				};

				gpg3-5 {
					samsung,pin-function = <0x00>;
					samsung,pin-pud = <0x01>;
					samsung,pins = "gpg3-5";
				};

				gpp0-4 {
					samsung,pin-function = <0x00>;
					samsung,pin-pud = <0x00>;
					samsung,pins = "gpp0-4";
				};

				gpp0-5 {
					samsung,pin-function = <0x00>;
					samsung,pin-pud = <0x00>;
					samsung,pins = "gpp0-5";
				};
			};

			sleep-state {
				linux,phandle = <0x28>;
				phandle = <0x28>;

				gpc1-2 {
					samsung,pin-con-pdn = <0x02>;
					samsung,pin-pud-pdn = <0x01>;
					samsung,pins = "gpc1-2";
				};

				gpc1-3 {
					samsung,pin-con-pdn = <0x02>;
					samsung,pin-pud-pdn = <0x01>;
					samsung,pins = "gpc1-3";
				};

				gpc2-2 {
					samsung,pin-con-pdn = <0x02>;
					samsung,pin-pud-pdn = <0x01>;
					samsung,pins = "gpc2-2";
				};

				gpc2-4 {
					samsung,pin-con-pdn = <0x02>;
					samsung,pin-pud-pdn = <0x01>;
					samsung,pins = "gpc2-4";
				};

				gpg0-1 {
					samsung,pin-con-pdn = <0x02>;
					samsung,pin-pud-pdn = <0x01>;
					samsung,pins = "gpg0-1";
				};

				gpg0-5 {
					samsung,pin-con-pdn = <0x03>;
					samsung,pin-pud-pdn = <0x00>;
					samsung,pins = "gpg0-5";
				};

				gpg0-6 {
					samsung,pin-con-pdn = <0x00>;
					samsung,pin-pud-pdn = <0x01>;
					samsung,pins = "gpg0-6";
				};

				gpg0-7 {
					samsung,pin-con-pdn = <0x02>;
					samsung,pin-pud-pdn = <0x01>;
					samsung,pins = "gpg0-7";
				};

				gpg1-2 {
					samsung,pin-con-pdn = <0x03>;
					samsung,pin-pud-pdn = <0x00>;
					samsung,pins = "gpg1-2";
				};

				gpg1-3 {
					samsung,pin-con-pdn = <0x03>;
					samsung,pin-pud-pdn = <0x00>;
					samsung,pins = "gpg1-3";
				};

				gpg1-4 {
					samsung,pin-con-pdn = <0x02>;
					samsung,pin-pud-pdn = <0x01>;
					samsung,pins = "gpg1-4";
				};

				gpg1-5 {
					samsung,pin-con-pdn = <0x02>;
					samsung,pin-pud-pdn = <0x01>;
					samsung,pins = "gpg1-5";
				};

				gpg2-0 {
					samsung,pin-con-pdn = <0x02>;
					samsung,pin-pud-pdn = <0x01>;
					samsung,pins = "gpg2-0";
				};

				gpg2-1 {
					samsung,pin-con-pdn = <0x02>;
					samsung,pin-pud-pdn = <0x01>;
					samsung,pins = "gpg2-1";
				};

				gpg2-2 {
					samsung,pin-con-pdn = <0x02>;
					samsung,pin-pud-pdn = <0x01>;
					samsung,pins = "gpg2-2";
				};

				gpg2-3 {
					samsung,pin-con-pdn = <0x02>;
					samsung,pin-pud-pdn = <0x01>;
					samsung,pins = "gpg2-3";
				};

				gpg2-4 {
					samsung,pin-con-pdn = <0x03>;
					samsung,pin-pud-pdn = <0x00>;
					samsung,pins = "gpg2-4";
				};

				gpg2-5 {
					samsung,pin-con-pdn = <0x02>;
					samsung,pin-pud-pdn = <0x01>;
					samsung,pins = "gpg2-5";
				};

				gpg2-6 {
					samsung,pin-con-pdn = <0x02>;
					samsung,pin-pud-pdn = <0x01>;
					samsung,pins = "gpg2-6";
				};

				gpg2-7 {
					samsung,pin-con-pdn = <0x02>;
					samsung,pin-pud-pdn = <0x01>;
					samsung,pins = "gpg2-7";
				};

				gpg3-0 {
					samsung,pin-con-pdn = <0x03>;
					samsung,pin-pud-pdn = <0x00>;
					samsung,pins = "gpg3-0";
				};

				gpg3-1 {
					samsung,pin-con-pdn = <0x03>;
					samsung,pin-pud-pdn = <0x00>;
					samsung,pins = "gpg3-1";
				};

				gpg3-2 {
					samsung,pin-con-pdn = <0x02>;
					samsung,pin-pud-pdn = <0x00>;
					samsung,pins = "gpg3-2";
				};

				gpg3-3 {
					samsung,pin-con-pdn = <0x02>;
					samsung,pin-pud-pdn = <0x00>;
					samsung,pins = "gpg3-3";
				};

				gpg3-4 {
					samsung,pin-con-pdn = <0x02>;
					samsung,pin-pud-pdn = <0x01>;
					samsung,pins = "gpg3-4";
				};

				gpg3-5 {
					samsung,pin-con-pdn = <0x02>;
					samsung,pin-pud-pdn = <0x01>;
					samsung,pins = "gpg3-5";
				};

				gpg4-0 {
					samsung,pin-con-pdn = <0x03>;
					samsung,pin-pud-pdn = <0x00>;
					samsung,pins = "gpg4-0";
				};

				gpg4-2 {
					samsung,pin-con-pdn = <0x03>;
					samsung,pin-pud-pdn = <0x00>;
					samsung,pins = "gpg4-2";
				};

				gpp0-0 {
					samsung,pin-con-pdn = <0x02>;
					samsung,pin-pud-pdn = <0x00>;
					samsung,pins = "gpp0-0";
				};

				gpp0-1 {
					samsung,pin-con-pdn = <0x02>;
					samsung,pin-pud-pdn = <0x00>;
					samsung,pins = "gpp0-1";
				};

				gpp0-2 {
					samsung,pin-con-pdn = <0x02>;
					samsung,pin-pud-pdn = <0x00>;
					samsung,pins = "gpp0-2";
				};

				gpp0-3 {
					samsung,pin-con-pdn = <0x02>;
					samsung,pin-pud-pdn = <0x00>;
					samsung,pins = "gpp0-3";
				};

				gpp0-4 {
					samsung,pin-con-pdn = <0x02>;
					samsung,pin-pud-pdn = <0x00>;
					samsung,pins = "gpp0-4";
				};

				gpp0-5 {
					samsung,pin-con-pdn = <0x02>;
					samsung,pin-pud-pdn = <0x00>;
					samsung,pins = "gpp0-5";
				};

				gpp0-6 {
					samsung,pin-con-pdn = <0x02>;
					samsung,pin-pud-pdn = <0x00>;
					samsung,pins = "gpp0-6";
				};

				gpp0-7 {
					samsung,pin-con-pdn = <0x02>;
					samsung,pin-pud-pdn = <0x00>;
					samsung,pins = "gpp0-7";
				};

				gpp1-0 {
					samsung,pin-con-pdn = <0x02>;
					samsung,pin-pud-pdn = <0x00>;
					samsung,pins = "gpp1-0";
				};

				gpp1-1 {
					samsung,pin-con-pdn = <0x02>;
					samsung,pin-pud-pdn = <0x00>;
					samsung,pins = "gpp1-1";
				};

				gpp1-2 {
					samsung,pin-con-pdn = <0x02>;
					samsung,pin-pud-pdn = <0x00>;
					samsung,pins = "gpp1-2";
				};

				gpp1-3 {
					samsung,pin-con-pdn = <0x02>;
					samsung,pin-pud-pdn = <0x00>;
					samsung,pins = "gpp1-3";
				};

				gpp1-4 {
					samsung,pin-con-pdn = <0x02>;
					samsung,pin-pud-pdn = <0x00>;
					samsung,pins = "gpp1-4";
				};

				gpp1-5 {
					samsung,pin-con-pdn = <0x02>;
					samsung,pin-pud-pdn = <0x00>;
					samsung,pins = "gpp1-5";
				};
			};
		};
	};

	fragment@6 {
		target = <0xffffffff>;

		__overlay__ {
			#address-cells = <0x01>;
			#size-cells = <0x00>;
			clock-frequency = <0x61a80>;
			gpios = <0xffffffff 0x06 0x00 0xffffffff 0x07 0x00>;
			pinctrl-0 = <0xffffffff>;
			pinctrl-1 = <0xffffffff>;
			pinctrl-2 = <0xffffffff>;
			pinctrl-names = "default\0on_i2c\0off_i2c";
			samsung,reset-before-trans;
			status = "okay";

			fimc-is-3l6@5A {
				compatible = "samsung,exynos5-fimc-is-cis-3l6";
				id = <0x03>;
				reg = <0x2d>;
				sensor_f_number = <0xdc>;
				setfile = "setB";
			};

			fimc-is-macro-gc5035@7E {
				compatible = "samsung,exynos5-fimc-is-cis-gc5035";
				id = <0x04>;
				reg = <0x3f>;
				sensor_f_number = <0xf0>;
				setfile = "setB";
			};
		};
	};

	fragment@60 {
		target = <0xffffffff>;

		__overlay__ {

			btp-irq {
				linux,phandle = <0x2b>;
				phandle = <0x2b>;
				samsung,pin-drv = <0x03>;
				samsung,pin-function = <0x0f>;
				samsung,pin-pud = <0x00>;
				samsung,pins = "gpa0-5";
			};

			btp-irq-sleep {
				linux,phandle = <0x29>;
				phandle = <0x29>;
				samsung,pin-drv = <0x03>;
				samsung,pin-function = <0x00>;
				samsung,pin-pud = <0x01>;
				samsung,pins = "gpa0-5";
			};
		};
	};

	fragment@61 {
		target = <0xffffffff>;

		__overlay__ {

			btp-rst {
				linux,phandle = <0x2a>;
				phandle = <0x2a>;
				samsung,pin-drv = <0x00>;
				samsung,pin-function = <0x01>;
				samsung,pin-pud = <0x01>;
				samsung,pins = "gpg3-0";
			};

			spi17-miso-inactive {
				linux,phandle = <0x31>;
				phandle = <0x31>;
				samsung,pin-drv = <0x02>;
				samsung,pin-function = <0x00>;
				samsung,pin-pud = <0x01>;
				samsung,pins = "gpp2-6";
			};

			spi7-bus-inactive {
				linux,phandle = <0x30>;
				phandle = <0x30>;
				samsung,pin-drv = <0x02>;
				samsung,pin-function = <0x01>;
				samsung,pin-pud = <0x00>;
				samsung,pin-val = <0x00>;
				samsung,pins = "gpp2-4\0gpp2-5\0gpp2-7";
			};

			spi7-clk {
				linux,phandle = <0x2c>;
				phandle = <0x2c>;
				samsung,pin-drv = <0x02>;
				samsung,pin-function = <0x02>;
				samsung,pin-pud = <0x01>;
				samsung,pins = "gpp2-4";
			};

			spi7-cs {
				linux,phandle = <0x2d>;
				phandle = <0x2d>;
				samsung,pin-drv = <0x02>;
				samsung,pin-function = <0x02>;
				samsung,pin-pud = <0x03>;
				samsung,pins = "gpp2-7";
			};

			spi7-miso {
				linux,phandle = <0x2e>;
				phandle = <0x2e>;
				samsung,pin-drv = <0x02>;
				samsung,pin-function = <0x02>;
				samsung,pin-pud = <0x01>;
				samsung,pins = "gpp2-6";
			};

			spi7-mosi {
				linux,phandle = <0x2f>;
				phandle = <0x2f>;
				samsung,pin-drv = <0x02>;
				samsung,pin-function = <0x02>;
				samsung,pin-pud = <0x01>;
				samsung,pins = "gpp2-5";
			};
		};
	};

	fragment@62 {
		target = <0xffffffff>;

		__overlay__ {
			#address-cells = <0x01>;
			#size-cells = <0x00>;
			dma-mode;
			dmas = <0xffffffff 0x15 0xffffffff 0x14>;
			status = "okay";

			etspi-spi@0 {
				#gpio-cells = <0x02>;
				compatible = "etspi,et5xx";
				etspi-chipid = "ET523";
				etspi-drdyPin = <0xffffffff 0x05 0x00>;
				etspi-orient = <0x02>;
				etspi-regulator = "VDD_BTP_3P3";
				etspi-sleepPin = <0xffffffff 0x00 0x00>;
				gpio-controller;
				pinctrl-0 = <0x29 0x2a>;
				pinctrl-1 = <0x2b 0x2c 0x2d 0x2e 0x2f>;
				pinctrl-2 = <0x29 0x30 0x31>;
				pinctrl-3 = <0x2b>;
				pinctrl-4 = <0x29>;
				pinctrl-names = "default\0pins_poweron\0pins_poweroff\0pins_poweron_tz\0pins_poweroff_tz";
				reg = <0x00>;
				spi-max-frequency = <0xc65d40>;

				controller-data {
					cs-gpio = <0xffffffff 0x07 0x00>;
					samsung,spi-chip-select-mode = <0x00>;
					samsung,spi-feedback-delay = <0x00>;
				};
			};
		};
	};

	fragment@63 {
		target = <0xffffffff>;

		__overlay__ {
			#address-cells = <0x01>;
			#size-cells = <0x00>;
			samsung,i2c-max-bus-freq = <0x61a80>;
			samsung,i2c-sda-delay = <0x64>;
			status = "okay";

			isg5320a@28 {
				compatible = "isg5320a";
				interrupt-parent = <0xffffffff>;
				interrupts = <0x04 0x00 0x00>;
				isg5320a,hallic_cert_detect = <0x00>;
				isg5320a,hallic_detect = <0x00>;
				isg5320a,irq-gpio = <0xffffffff 0x04 0x00>;
				pinctrl-0 = <0x32>;
				pinctrl-names = "default";
				reg = <0x28>;
				status = "okay";
			};

			isg5320a_sub@2C {
				compatible = "isg5320a_sub";
				interrupt-parent = <0xffffffff>;
				interrupts = <0x07 0x00 0x00>;
				isg5320a_sub,hallic_cert_detect = <0x00>;
				isg5320a_sub,hallic_detect = <0x00>;
				isg5320a_sub,irq-gpio = <0xffffffff 0x07 0x00>;
				pinctrl-0 = <0x33>;
				pinctrl-names = "default";
				reg = <0x2c>;
				status = "okay";
			};
		};
	};

	fragment@64 {
		target = <0xffffffff>;

		__overlay__ {

			grip-int {
				linux,phandle = <0x32>;
				phandle = <0x32>;
				samsung,pin-function = <0x0f>;
				samsung,pin-pud = <0x00>;
				samsung,pins = "gpa0-4";
			};

			grip-sub-int {
				linux,phandle = <0x33>;
				phandle = <0x33>;
				samsung,pin-function = <0x0f>;
				samsung,pin-pud = <0x00>;
				samsung,pins = "gpa2-7";
			};
		};
	};

	fragment@7 {
		target = <0xffffffff>;

		__overlay__ {
			#address-cells = <0x01>;
			#size-cells = <0x00>;
			clock-frequency = <0x61a80>;
			gpios = <0xffffffff 0x01 0x00 0xffffffff 0x00 0x00>;
			pinctrl-0 = <0xffffffff>;
			pinctrl-1 = <0xffffffff>;
			pinctrl-2 = <0xffffffff>;
			pinctrl-names = "default\0on_i2c\0off_i2c";
			samsung,reset-before-trans;
			status = "okay";

			rear3_eeprom@A8 {
				compatible = "samsung,rear3-eeprom-i2c";
				reg = <0x54>;
			};

			rear4_eeprom@A4 {
				compatible = "samsung,rear4-eeprom-i2c";
				reg = <0x52>;
			};
		};
	};

	fragment@8 {
		target = <0xffffffff>;

		__overlay__ {
			#address-cells = <0x01>;
			#size-cells = <0x00>;
			clock-frequency = <0x61a80>;
			gpios = <0xffffffff 0x03 0x00 0xffffffff 0x02 0x00>;
			pinctrl-0 = <0xffffffff>;
			pinctrl-1 = <0xffffffff>;
			pinctrl-2 = <0xffffffff>;
			pinctrl-names = "default\0on_i2c\0off_i2c";
			samsung,reset-before-trans;
			status = "okay";

			fimc-is-actuator@18 {
				compatible = "samsung,exynos5-fimc-is-actuator-dw9817";
				id = <0x00>;
				place = <0x00>;
				reg = <0x0c>;
			};

			front_eeprom@A2 {
				compatible = "samsung,front-eeprom-i2c";
				reg = <0x51>;
			};

			rear_eeprom@B0 {
				compatible = "samsung,rear-eeprom-i2c";
				reg = <0x58>;
				use_dualcam_set_cal;
			};
		};
	};

	fragment@9 {
		target = <0xffffffff>;

		__overlay__ {

			s2mu106@3D {

				flash_led {
					default_current = <0x32>;
					default_timer = <0x00>;
					factory_current = <0x15e>;
					flash-gpio = <0xffffffff 0x06 0x01>;
					flash_current = <0x5dc>;
					flashlight_current = <0x32 0x50 0x6e 0xaf 0xf0>;
					max_current = <0xc8>;
					movie_current = <0x96>;
					preflash_current = <0xaf>;
					status = "okay";
					torch-gpio = <0xffffffff 0x03 0x01>;
					torch_current = <0x5a>;
				};
			};
		};
	};

	fragment@battery {
		target-path = "/";

		__overlay__ {

			battery {
				#io-channel-cells = <0x05>;
				battery,adc_check_count = <0x05>;
				battery,age_data = <0x00 0x111c 0x10d6 0x10ea 0x5d 0x12c 0x1108 0x10c2 0x10d6 0x5c 0x190 0x10f4 0x10ae 0x10c2 0x5b 0x2bc 0x10e0 0x109a 0x10ae 0x5a 0x3e8 0x10ae 0x1068 0x107c 0x59>;
				battery,batt_data_version = <0x01>;
				battery,battery_check_type = <0x00>;
				battery,battery_full_capacity = <0x1770>;
				battery,cable_check_type = <0x04>;
				battery,cable_source_type = <0x01>;
				battery,charger_name = "sec-direct-charger";
				battery,charging_reset_time = <0x00>;
				battery,charging_total_time = <0x3840>;
				battery,check_adc_max = <0x5a0>;
				battery,check_adc_min = <0x00>;
				battery,check_count = <0x00>;
				battery,chg_charging_limit_current = <0x6a4>;
				battery,chg_float_voltage = <0x111c>;
				battery,chg_float_voltage_conv = <0x01>;
				battery,chg_gpio_full_check = <0x00>;
				battery,chg_high_temp = <0x1ea>;
				battery,chg_high_temp_recovery = <0x1c2>;
				battery,chg_input_limit_current = <0x3e8>;
				battery,chg_polarity_full_check = <0x01>;
				battery,chg_temp_check_type = <0x02>;
				battery,chg_temp_table_adc = <0x11d 0x140 0x17c 0x1c2 0x210 0x269 0x2e7 0x352 0x3e0 0x482 0x53e 0x601 0x6ac 0x7be 0x87a 0x992 0xa7f 0xb54 0xc1a 0xcc8 0xd55 0xd8b 0xe46>;
				battery,chg_temp_table_data = <0x384 0x352 0x320 0x2ee 0x2bc 0x28a 0x258 0x226 0x1f4 0x1c2 0x190 0x15e 0x12c 0xfa 0xc8 0x96 0x64 0x32 0x00 0xffffffce 0xffffff9c 0xffffff6a 0xffffff38>;
				battery,chg_thermal_source = <0x00>;
				battery,chip_vendor = "LSI";
				battery,cisd_alg_index = <0x08>;
				battery,cisd_max_voltage_thr = <0x1388>;
				battery,coil_thermal_source = <0x02>;
				battery,cv_data = <0xd38 0x322 0x820 0xcca 0x32b 0x7ed 0xc32 0x334 0x7b0 0xba9 0x33e 0x773 0xb01 0x349 0x72c 0xa4c 0x352 0x6e5 0x9f2 0x35c 0x69e 0x91e 0x366 0x642 0x8e3 0x370 0x5fb 0x861 0x37a 0x596 0x7be 0x384 0x540 0x735 0x38e 0x4da 0x6db 0x398 0x46a 0x639 0x3a2 0x3fa 0x598 0x3ac 0x376 0x53b 0x3b6 0x2de 0x4bf 0x3c0 0x24f 0x42c 0x3ca 0x1ac 0x3e2 0x3d4 0x109 0x3a7 0x3de 0x8f 0x381 0x3e8 0x00>;
				battery,dc_step_chg_charge_power = <0x55f0>;
				battery,dc_step_chg_cond_iin = <0x79e 0x708 0x00>;
				battery,dc_step_chg_cond_soc = <0x0c 0x32 0x64>;
				battery,dc_step_chg_cond_vol = <0xffa 0x105e 0x111c>;
				battery,dc_step_chg_iin_check_cnt = <0x03>;
				battery,dc_step_chg_step = <0x03>;
				battery,dc_step_chg_type = <0xe9>;
				battery,dc_step_chg_val_iout = <0x12c0 0xf3c 0xe10>;
				battery,dc_step_chg_val_vfloat = <0xffa 0x105e 0x111c>;
				battery,dchg_charging_limit_current = <0x7d0>;
				battery,dchg_high_batt_temp = <0x190>;
				battery,dchg_high_batt_temp_recovery = <0x17c>;
				battery,dchg_high_temp = <0x1ea>;
				battery,dchg_high_temp_recovery = <0x1c2>;
				battery,dchg_input_limit_current = <0x3e8>;
				battery,dchg_temp_check_type = <0x01>;
				battery,dchg_thermal_source = <0x00>;
				battery,enable_noise_wa;
				battery,enable_sysovlo_irq;
				battery,expired_time = <0x2c88>;
				battery,fgsrc_switch_name = "s2mu106-fuelgauge";
				battery,fuelgauge_name = "s2mu106-fuelgauge";
				battery,full_check_count = <0x01>;
				battery,full_check_type = <0x02>;
				battery,full_check_type_2nd = <0x02>;
				battery,full_condition_soc = <0x5d>;
				battery,full_condition_type = <0x0d>;
				battery,full_condition_vcell = <0x10ea>;
				battery,health_condition = <0x384 0x00 0x4b0 0x00 0x5dc 0x00>;
				battery,high_temp_float = <0x1036>;
				battery,high_temp_topoff = <0x12c>;
				battery,hv_charging_total_time = <0x2a30>;
				battery,ignore_cisd_index = <0x00 0x3c0>;
				battery,ignore_cisd_index_d = <0x00 0x78>;
				battery,inbat_voltage = <0x01>;
				battery,inbat_voltage_table_adc = <0xb01 0xaf3 0xadf 0xac1 0xaa8 0xa8d 0xa78 0xa5e 0xa44 0xa25 0xa05 0x9e8 0x9cd 0x9ae 0x992 0x97a 0x961 0x944 0x927 0x911 0x8f2>;
				battery,inbat_voltage_table_data = <0x111f 0x1100 0x10d2 0x109d 0x106c 0x1038 0x1005 0xfd5 0xfa2 0xf72 0xf3f 0xf0c 0xed9 0xea6 0xe76 0xe46 0xe11 0xde0 0xdaf 0xd80 0xd4a>;
				battery,low_temp_float = <0x111c>;
				battery,low_temp_topoff = <0x12c>;
				battery,max_charging_charge_power = <0x61a8>;
				battery,max_charging_current = <0xc4e>;
				battery,max_input_current = <0xbb8>;
				battery,max_input_voltage = <0x2328>;
				battery,mix_high_chg_temp = <0x1f4>;
				battery,mix_high_temp = <0x1a4>;
				battery,mix_high_temp_recovery = <0x186>;
				battery,monitor_initial_count = <0x00>;
				battery,normal_charging_total_time = <0x4650>;
				battery,overheatlimit_recovery = <0x2a8>;
				battery,overheatlimit_threshold = <0x2bc>;
				battery,ovp_uvlo_check_type = <0x03>;
				battery,pd_charging_charge_power = <0x3a98>;
				battery,polling_time = <0x0a 0x1e 0x1e 0x1e 0xe10>;
				battery,polling_type = <0x01>;
				battery,pre_afc_input_current = <0x1f4>;
				battery,pre_afc_work_delay = <0x7d0>;
				battery,pre_wc_afc_input_current = <0x1f4>;
				battery,pre_wc_afc_work_delay = <0xfa0>;
				battery,prepare_ta_delay = <0x00>;
				battery,recharge_check_count = <0x01>;
				battery,recharge_condition_soc = <0x62>;
				battery,recharge_condition_type = <0x04>;
				battery,recharge_condition_vcell = <0x10d6>;
				battery,recharging_expired_time = <0x1518>;
				battery,recharging_total_time = <0x1518>;
				battery,rp_current_abnormal_rp3 = <0x708>;
				battery,rp_current_rdu_rp3 = <0x834>;
				battery,rp_current_rp1 = <0x1f4>;
				battery,rp_current_rp2 = <0x5dc>;
				battery,rp_current_rp3 = <0xbb8>;
				battery,siop_apdo_charging_limit_current = <0x7d0>;
				battery,siop_apdo_input_limit_current = <0x4b0>;
				battery,siop_call_cc_current = <0x14a>;
				battery,siop_call_cv_current = <0x14a>;
				battery,siop_charging_limit_current = <0x3e8>;
				battery,siop_event_check_type = <0x01>;
				battery,siop_hv_charging_limit_current = <0x3e8>;
				battery,siop_hv_input_limit_current = <0x2bc>;
				battery,siop_hv_input_limit_current_2nd = <0x1c2>;
				battery,siop_hv_wireless_charging_limit_current = <0x2bc>;
				battery,siop_hv_wireless_input_limit_current = <0x258>;
				battery,siop_input_limit_current = <0x4b0>;
				battery,siop_store_hv_wireless_input_limit_current = <0x1c2>;
				battery,siop_wireless_charging_limit_current = <0x2bc>;
				battery,siop_wireless_input_limit_current = <0x258>;
				battery,sleep_mode_limit_current = <0x1f4>;
				battery,standard_curr = <0xe10>;
				battery,step_charging_charge_power = <0x2ee0>;
				battery,step_charging_condition = <0x2d 0x64>;
				battery,step_charging_condition_curr = <0xc4e 0xc4e>;
				battery,step_charging_current = <0xc4e 0xc4e>;
				battery,step_charging_float_voltage = <0x1036 0x111c>;
				battery,step_charging_type = <0x00>;
				battery,swelling_high_rechg_voltage = <0xfa0>;
				battery,swelling_low_rechg_voltage = <0x1086>;
				battery,ta_alert_wa;
				battery,technology = <0x02>;
				battery,temp_adc_type = <0x01>;
				battery,temp_check_count = <0x01>;
				battery,temp_check_type = <0x02>;
				battery,temp_gap_bat_usb = <0xc8>;
				battery,temp_table_adc = <0x136 0x159 0x195 0x1dd 0x227 0x285 0x310 0x36c 0x3fb 0x49d 0x556 0x61a 0x6f9 0x7d6 0x8b5 0x9ab 0xa91 0xb63 0xc28 0xcf6 0xd6e 0xdd3 0xe61>;
				battery,temp_table_data = <0x384 0x352 0x320 0x2ee 0x2bc 0x28a 0x258 0x226 0x1f4 0x1c2 0x190 0x15e 0x12c 0xfa 0xc8 0x96 0x64 0x32 0x00 0xffffffce 0xffffff9c 0xffffff6a 0xffffff38>;
				battery,thermal_source = <0x02>;
				battery,ttf_capacity = <0x11f8>;
				battery,ttf_dc25_charge_current = <0xd0c>;
				battery,ttf_hv_charge_current = <0xa8c>;
				battery,usb_charging_total_time = <0x8ca0>;
				battery,usb_protection_temp = <0x262>;
				battery,usb_temp_check_type = <0x00>;
				battery,usb_temp_table_adc = <0x126 0x159 0x194 0x1da 0x22e 0x28f 0x301 0x377 0x3fd 0x4a5 0x562 0x632 0x713 0x800 0x8f3 0x9d0 0xaa6 0xb74 0xc32 0xcdd 0xd75 0xdf7 0xe66>;
				battery,usb_temp_table_data = <0x384 0x352 0x320 0x2ee 0x2bc 0x28a 0x258 0x226 0x1f4 0x1c2 0x190 0x15e 0x12c 0xfa 0xc8 0x96 0x64 0x32 0x00 0xffffffce 0xffffff9c 0xffffff6a 0xffffff38>;
				battery,usb_thermal_source = <0x02>;
				battery,vendor = "Battery";
				battery,wc_cv_current = <0x334>;
				battery,wc_cv_pack_current = <0x276>;
				battery,wc_full_input_limit_current = <0x64>;
				battery,wc_hero_stand_cc_cv = <0x46>;
				battery,wc_hero_stand_cv_current = <0x258>;
				battery,wc_hero_stand_hv_cv_current = <0x1c2>;
				battery,wire_cold_cool3_thresh = <0x00>;
				battery,wire_cool1_current = <0xc4e>;
				battery,wire_cool1_normal_thresh = <0xb4>;
				battery,wire_cool2_cool1_thresh = <0x96>;
				battery,wire_cool2_current = <0x546>;
				battery,wire_cool3_cool2_thresh = <0x32>;
				battery,wire_cool3_current = <0x226>;
				battery,wire_normal_warm_thresh = <0x19a>;
				battery,wire_warm_current = <0x802>;
				battery,wire_warm_overheat_thresh = <0x1f4>;
				battery,wireless_cold_cool3_thresh = <0x00>;
				battery,wireless_cool1_current = <0xc4e>;
				battery,wireless_cool1_normal_thresh = <0xb4>;
				battery,wireless_cool2_cool1_thresh = <0x96>;
				battery,wireless_cool2_current = <0x41a>;
				battery,wireless_cool3_cool2_thresh = <0x32>;
				battery,wireless_cool3_current = <0x1c2>;
				battery,wireless_normal_warm_thresh = <0x19a>;
				battery,wireless_warm_current = <0x41a>;
				battery,wireless_warm_overheat_thresh = <0x1c2>;
				battery,wpc_charging_limit_current = <0x1c2>;
				battery,wpc_high_temp = <0x19a>;
				battery,wpc_high_temp_recovery = <0x190>;
				battery,wpc_lcd_on_high_temp = <0x1ae>;
				battery,wpc_lcd_on_high_temp_rec = <0x12c>;
				battery,wpc_store_high_temp = <0x19a>;
				battery,wpc_store_high_temp_recovery = <0x190>;
				battery,wpc_store_lcd_on_high_temp = <0x17c>;
				battery,wpc_store_lcd_on_high_temp_rec = <0x12c>;
				battery,wpc_temp_check_type = <0x00>;
				battery,wpc_temp_control_source = <0x01>;
				battery,wpc_temp_table_adc = <0x126 0x159 0x194 0x1da 0x22e 0x28f 0x301 0x377 0x3fd 0x4a5 0x562 0x632 0x713 0x800 0x8f3 0x9d0 0xaa6 0xb74 0xc32 0xcdd 0xd75 0xdf7 0xe66>;
				battery,wpc_temp_table_data = <0x384 0x352 0x320 0x2ee 0x2bc 0x28a 0x258 0x226 0x1f4 0x1c2 0x190 0x15e 0x12c 0xfa 0xc8 0x96 0x64 0x32 0x00 0xffffffce 0xffffff9c 0xffffff6a 0xffffff38>;
				battery,wpc_thermal_source = <0x02>;
				compatible = "samsung,sec-battery";
				io-channel-names = "adc-temp\0adc-in-bat";
				io-channel-ranges;
				io-channels = <0xffffffff 0x01 0xffffffff 0x02>;
				pinctrl-names = "default";
				status = "okay";
			};

			battery_params {
				battery,battery_data = <0x2c 0x0b 0xb0 0x0a 0x35 0x0a 0xbd 0x09 0x49 0x09 0xdb 0x08 0x74 0x08 0x16 0x08 0xc2 0x07 0x56 0x07 0xfc 0x06 0xc3 0x06 0x97 0x06 0x73 0x06 0x55 0x06 0x33 0x06 0x04 0x06 0xd5 0x05 0x93 0x05 0x7e 0x05 0x99 0x03 0x6b 0x01 0x6b 0x08 0x00 0x08 0x95 0x07 0x2a 0x07 0xbe 0x06 0x53 0x06 0xe8 0x05 0x7d 0x05 0x11 0x05 0xa6 0x04 0x3b 0x04 0xd0 0x03 0x64 0x03 0xf9 0x02 0x8e 0x02 0x23 0x02 0xb8 0x01 0x4c 0x01 0xe1 0x00 0x76 0x00 0x0b 0x00 0xe9 0x0f 0x0a 0x0a 0x0a 0x0a 0x29 0x29 0x29 0x29 0x29 0x29 0x2a 0x2b 0x2b 0x2b 0x2b 0x2b 0x2b 0x2c 0x2d 0x2e 0x33 0x9a 0x68 0x56 0x33 0x10 0x00 0x08 0x291c 0x2710 0x2504 0x22f9 0x20ed 0x1ee2 0x1cd6 0x1aca 0x18bf 0x16b3 0x14a8 0x129c 0x1091 0xe85 0xc7a 0xa6e 0x862 0x657 0x44b 0x240 0x34 0xffffff91 0xabbb 0xa961 0xa707 0xa4bf 0xa288 0xa06d 0x9e76 0x9cac 0x9b10 0x9902 0x9749 0x9636 0x955d 0x94ad 0x941b 0x9375 0x9291 0x91a9 0x9069 0x9001 0x86c0 0x7c1b 0x00 0x2c 0x0b 0xb0 0x0a 0x35 0x0a 0xbd 0x09 0x49 0x09 0xdb 0x08 0x74 0x08 0x16 0x08 0xc2 0x07 0x56 0x07 0xfc 0x06 0xc3 0x06 0x97 0x06 0x73 0x06 0x55 0x06 0x33 0x06 0x04 0x06 0xd5 0x05 0x93 0x05 0x7e 0x05 0x99 0x03 0x6b 0x01 0x88 0x08 0x1c 0x08 0xb0 0x07 0x43 0x07 0xd7 0x06 0x6a 0x06 0xfe 0x05 0x92 0x05 0x25 0x05 0xb9 0x04 0x4c 0x04 0xe0 0x03 0x74 0x03 0x07 0x03 0x9b 0x02 0x2f 0x02 0xc2 0x01 0x56 0x01 0xea 0x00 0x7d 0x00 0x11 0x00 0xef 0x0f 0x0a 0x0a 0x0a 0x0a 0x29 0x29 0x29 0x29 0x29 0x29 0x2a 0x2b 0x2b 0x2b 0x2b 0x2b 0x2b 0x2c 0x2d 0x2e 0x33 0x9a 0xec 0x55 0x1c 0x10 0x00 0x08 0x29a9 0x2798 0x2587 0x2376 0x2165 0x1f54 0x1d43 0x1b31 0x1920 0x170f 0x14fe 0x12ec 0x10db 0xeca 0xcb9 0xaa8 0x897 0x686 0x475 0x263 0x52 0xffffffae 0xabbb 0xa961 0xa707 0xa4bf 0xa288 0xa06d 0x9e76 0x9cac 0x9b10 0x9902 0x9749 0x9636 0x955d 0x94ad 0x941b 0x9375 0x9291 0x91a9 0x9069 0x9001 0x86c0 0x7c1b 0x00 0x2c 0x0b 0xb0 0x0a 0x35 0x0a 0xbd 0x09 0x49 0x09 0xdb 0x08 0x74 0x08 0x16 0x08 0xc2 0x07 0x56 0x07 0xfc 0x06 0xc3 0x06 0x97 0x06 0x73 0x06 0x55 0x06 0x33 0x06 0x04 0x06 0xd5 0x05 0x93 0x05 0x7e 0x05 0x99 0x03 0x6b 0x01 0xaf 0x08 0x40 0x08 0xd2 0x07 0x64 0x07 0xf6 0x06 0x87 0x06 0x19 0x06 0xab 0x05 0x3c 0x05 0xce 0x04 0x60 0x04 0xf2 0x03 0x83 0x03 0x15 0x03 0xa7 0x02 0x38 0x02 0xca 0x01 0x5c 0x01 0xee 0x00 0x7f 0x00 0x11 0x00 0xef 0x0f 0x0a 0x0a 0x0a 0x0a 0x29 0x29 0x29 0x29 0x29 0x29 0x2a 0x2b 0x2b 0x2b 0x2b 0x2b 0x2b 0x2c 0x2d 0x2e 0x33 0x9a 0x70 0x54 0xd5 0x0f 0x00 0x08 0x2a65 0x284a 0x2630 0x2415 0x21fb 0x1fe1 0x1dc6 0x1bab 0x1991 0x1776 0x155c 0x1341 0x1127 0xf0d 0xcf2 0xad8 0x8bd 0x6a3 0x489 0x26e 0x54 0xffffffac 0xabbb 0xa961 0xa707 0xa4bf 0xa288 0xa06d 0x9e76 0x9cac 0x9b10 0x9902 0x9749 0x9636 0x955d 0x94ad 0x941b 0x9375 0x9291 0x91a9 0x9069 0x9001 0x86c0 0x7c1b 0x00 0x2c 0x0b 0xb0 0x0a 0x35 0x0a 0xbd 0x09 0x49 0x09 0xdb 0x08 0x74 0x08 0x16 0x08 0xc2 0x07 0x56 0x07 0xfc 0x06 0xc3 0x06 0x97 0x06 0x73 0x06 0x55 0x06 0x33 0x06 0x04 0x06 0xd5 0x05 0x93 0x05 0x7e 0x05 0x99 0x03 0x6b 0x01 0xe5 0x08 0x74 0x08 0x03 0x08 0x92 0x07 0x21 0x07 0xb0 0x06 0x3f 0x06 0xce 0x05 0x5d 0x05 0xec 0x04 0x7b 0x04 0x0a 0x04 0x99 0x03 0x28 0x03 0xb7 0x02 0x46 0x02 0xd5 0x01 0x65 0x01 0xf4 0x00 0x83 0x00 0x12 0x00 0xee 0x0f 0x0a 0x0a 0x0a 0x0a 0x29 0x29 0x29 0x29 0x29 0x29 0x2a 0x2b 0x2b 0x2b 0x2b 0x2b 0x2b 0x2c 0x2d 0x2e 0x33 0x9a 0x68 0x52 0x73 0x0f 0x00 0x08 0x2b70 0x2948 0x2720 0x24f9 0x22d1 0x20a9 0x1e82 0x1c59 0x1a32 0x180a 0x15e2 0x13bb 0x1193 0xf6b 0xd44 0xb1c 0x8f4 0x6cd 0x4a5 0x27d 0x56 0xffffffaa 0xabbb 0xa961 0xa707 0xa4bf 0xa288 0xa06d 0x9e76 0x9cac 0x9b10 0x9902 0x9749 0x9636 0x955d 0x94ad 0x941b 0x9375 0x9291 0x91a9 0x9069 0x9001 0x86c0 0x7c1b 0x00 0x2c 0x0b 0xb0 0x0a 0x35 0x0a 0xbd 0x09 0x49 0x09 0xdb 0x08 0x74 0x08 0x16 0x08 0xc2 0x07 0x56 0x07 0xfc 0x06 0xc3 0x06 0x97 0x06 0x73 0x06 0x55 0x06 0x33 0x06 0x04 0x06 0xd5 0x05 0x93 0x05 0x7e 0x05 0x99 0x03 0x6b 0x01 0x4d 0x09 0xd7 0x08 0x61 0x08 0xeb 0x07 0x75 0x07 0xfe 0x06 0x88 0x06 0x12 0x06 0x9c 0x05 0x26 0x05 0xb0 0x04 0x39 0x04 0xc3 0x03 0x4d 0x03 0xd7 0x02 0x61 0x02 0xeb 0x01 0x75 0x01 0xff 0x00 0x89 0x00 0x12 0x00 0xee 0x0f 0x0a 0x0a 0x0a 0x0a 0x29 0x29 0x29 0x29 0x29 0x29 0x2a 0x2b 0x2b 0x2b 0x2b 0x2b 0x2b 0x2c 0x2d 0x2e 0x33 0x9a 0xd4 0x4e 0xc7 0x0e 0x00 0x08 0x2d6a 0x2b29 0x28e8 0x26a8 0x2467 0x2226 0x1fe5 0x1da4 0x1b63 0x1922 0x16e2 0x14a1 0x1260 0x101f 0xdde 0xb9e 0x95d 0x71c 0x4db 0x29b 0x5a 0xffffffa6 0xabbb 0xa961 0xa707 0xa4bf 0xa288 0xa06d 0x9e76 0x9cac 0x9b10 0x9902 0x9749 0x9636 0x955d 0x94ad 0x941b 0x9375 0x9291 0x91a9 0x9069 0x9001 0x86c0 0x7c1b 0x00>;
			};

			cable-info {
				default_charging_current = <0x834>;
				default_input_current = <0x708>;
				full_check_current_1st = <0x384>;
				full_check_current_2nd = <0x12c>;

				current_group_1 {
					cable_number = <0x02 0x13 0x15 0x16 0x17>;
					charging_current = <0x1f4>;
					input_current = <0x1f4>;
				};

				current_group_10 {
					cable_number = <0x0b 0x0e 0x10 0x1c 0x23>;
					charging_current = <0xc4e>;
					input_current = <0x2ee>;
				};

				current_group_11 {
					cable_number = <0x1d 0x25>;
					charging_current = <0x578>;
					input_current = <0x1f4>;
				};

				current_group_12 {
					cable_number = <0x01 0x04 0x1e>;
					charging_current = <0x226>;
					input_current = <0x1db>;
				};

				current_group_14 {
					cable_number = <0x22>;
					charging_current = <0xc4e>;
					input_current = <0x4b0>;
				};

				current_group_2 {
					cable_number = <0x19 0x1f>;
					charging_current = <0x3e8>;
					input_current = <0x3e8>;
				};

				current_group_3 {
					cable_number = <0x05 0x20>;
					charging_current = <0x5dc>;
					input_current = <0x5dc>;
				};

				current_group_4 {
					cable_number = <0x06 0x07 0x08 0x11 0x12>;
					charging_current = <0xc4e>;
					input_current = <0x672>;
				};

				current_group_5 {
					cable_number = <0x09>;
					charging_current = <0xc4e>;
					input_current = <0x672>;
				};

				current_group_6 {
					cable_number = <0x0a 0x0c 0x0f 0x1b 0x21 0x24>;
					charging_current = <0xc4e>;
					input_current = <0x320>;
				};

				current_group_7 {
					cable_number = <0x0d>;
					charging_current = <0xc4e>;
					input_current = <0x2bc>;
				};

				current_group_8 {
					cable_number = <0x18>;
					charging_current = <0x1c2>;
					input_current = <0x3e8>;
				};

				current_group_9 {
					cable_number = <0x1a>;
					charging_current = <0x708>;
					input_current = <0x7d0>;
				};
			};

			pdic-manager {
				pdic,giveback = <0x00>;
				pdic,max_current = <0x7d0>;
				pdic,max_power = <0x1388>;
				pdic,max_voltage = <0x1770>;
				pdic,min_current = <0x1f4>;
				pdic,no_usb_suspend = <0x01>;
				pdic,op_power = <0x9c4>;
				pdic,usb_com_capable = <0x01>;
				sink,capable_max_voltage = <0x1388>;
				source,max_power = <0x9c4>;
				source,max_voltage = <0x1388>;
				source,min_voltage = <0xfa0>;
			};

			s2mu106-charger {
				compatible = "samsung,s2mu106-charger";
				status = "disable";
			};

			sec-direct-charger {
				charger,battery_name = "battery";
				charger,dchg_min_current = <0x7d0>;
				charger,dchg_temp_high_threshold = <0x19a>;
				charger,dchg_temp_low_threshold = <0xb4>;
				charger,direct_charger = "sm5440-charger";
				charger,main_charger = "s2mu106-charger";
				compatible = "samsung,sec-direct-charger";
				status = "okay";
			};
		};
	};

	fragment@camera {
		target-path = "/";

		__overlay__ {

			fimc-is-flash-gpio@0 {
				compatible = "samsung,sensor-flash-s2mu106";
				flash-gpio = <0xffffffff 0x06 0x01>;
				id = <0x00 0x04>;
				linux,phandle = <0x36>;
				phandle = <0x36>;
				status = "okay";
				torch-gpio = <0xffffffff 0x03 0x01>;
			};

			fimc-is_macro_sensor_gc5035@7E {
				compatible = "samsung,sensor-module-gc5035";
				gpio_cam_a2p8_1p2_en = <0xffffffff 0x00 0x01>;
				gpio_mclk = <0xffffffff 0x02 0x01>;
				gpio_reset = <0xffffffff 0x02 0x01>;
				id = <0x04>;
				linux,phandle = <0x39>;
				mclk_ch = <0x02>;
				phandle = <0x39>;
				pinctrl-0;
				pinctrl-1 = <0xffffffff>;
				pinctrl-2 = <0xffffffff>;
				pinctrl-3;
				pinctrl-names = "pin0\0pin1\0pin2\0release";
				position = <0x06>;
				shared_mclk;
				status = "okay";
				use_2nd_module;

				flash {
					product_name = <0x0e>;
				};
			};

			fimc-is_sensor_3l6@5A {
				compatible = "samsung,sensor-module-3l6";
				gpio_ldo_en = <0xffffffff 0x06 0x01>;
				gpio_mclk = <0xffffffff 0x02 0x01>;
				gpio_reset = <0xffffffff 0x04 0x01>;
				id = <0x03>;
				linux,phandle = <0x38>;
				mclk_ch = <0x02>;
				phandle = <0x38>;
				pinctrl-0;
				pinctrl-1 = <0xffffffff>;
				pinctrl-2 = <0xffffffff>;
				pinctrl-3;
				pinctrl-names = "pin0\0pin1\0pin2\0release";
				position = <0x04>;
				shared_mclk;
				status = "okay";
			};

			fimc-is_sensor_gc5035@6E {
				compatible = "samsung,sensor-module-gc5035";
				gpio_mclk = <0xffffffff 0x00 0x01>;
				gpio_reset = <0xffffffff 0x07 0x01>;
				id = <0x02>;
				linux,phandle = <0x37>;
				mclk_ch = <0x00>;
				phandle = <0x37>;
				pinctrl-0;
				pinctrl-1 = <0xffffffff>;
				pinctrl-2 = <0xffffffff>;
				pinctrl-3;
				pinctrl-names = "pin0\0pin1\0pin2\0release";
				position = <0x02>;
				sensor_module_type = <0x01>;
				shared_mclk;
				status = "okay";
				use_sensor_otp;
			};

			fimc-is_sensor_imx616@34 {
				compatible = "samsung,sensor-module-imx616";
				gpio_mclk = <0xffffffff 0x01 0x01>;
				gpio_reset = <0xffffffff 0x07 0x01>;
				id = <0x01>;
				linux,phandle = <0x3a>;
				mclk_ch = <0x01>;
				phandle = <0x3a>;
				pinctrl-0;
				pinctrl-1 = <0xffffffff>;
				pinctrl-2 = <0xffffffff>;
				pinctrl-3;
				pinctrl-names = "pin0\0pin1\0pin2\0release";
				position = <0x01>;
				sensor_i2c_ch = <0x00>;
				status = "okay";

				internal_vc {
					vc_list = <0x02 0x05 0x00 0x03 0x03 0x00>;
				};
			};

			fimc-is_sensor_imx682@34 {
				compatible = "samsung,sensor-module-imx682";
				gpio_ldo_en = <0xffffffff 0x04 0x01>;
				gpio_mclk = <0xffffffff 0x00 0x01>;
				gpio_reset = <0xffffffff 0x01 0x01>;
				id = <0x00>;
				linux,phandle = <0x35>;
				mclk_ch = <0x00>;
				phandle = <0x35>;
				pinctrl-0 = <0xffffffff>;
				pinctrl-1 = <0xffffffff>;
				pinctrl-2;
				pinctrl-3;
				pinctrl-names = "pin0\0pin1\0pin2\0release";
				position = <0x00>;
				sensor_i2c_addr = <0x1a>;
				sensor_i2c_ch = <0x01>;
				shared_mclk;
				status = "okay";
				use_pdaf;

				af {
					i2c_addr = <0x18>;
					i2c_ch = <0x05>;
					product_name = <0x1a>;
				};

				flash {
					product_name = <0x0e>;
				};

				internal_vc {
					vc_list = <0x02 0x02 0x01 0x03 0x04 0x01>;
				};
			};
		};
	};

	fragment@inputbooster {
		target-path = "/";

		__overlay__ {

			input_booster {
				#address-cells = <0x01>;
				#size-cells = <0x00>;
				compatible = "input_booster";
				status = "okay";

				booster_key@1 {
					input_booster,cpu_freqs = <0x1174c0>;
					input_booster,dma_latency = <0x00>;
					input_booster,head_times = <0x1f4>;
					input_booster,hmp_boost = <0x01>;
					input_booster,int_freqs = <0x00>;
					input_booster,kfc_freqs = <0x00>;
					input_booster,label = "KEY";
					input_booster,levels = <0x01>;
					input_booster,mif_freqs = <0x00>;
					input_booster,phase_times = <0x00>;
					input_booster,tail_times = <0x1f4>;
					input_booster,type = <0x00>;
				};

				booster_key@10 {
					input_booster,cpu_freqs = <0x1702a0>;
					input_booster,dma_latency = <0x00>;
					input_booster,head_times = <0x2bc>;
					input_booster,hmp_boost = <0x01>;
					input_booster,int_freqs = <0x00>;
					input_booster,kfc_freqs = <0x101148>;
					input_booster,label = "KEY_TWO";
					input_booster,levels = <0x01>;
					input_booster,mif_freqs = <0x00>;
					input_booster,phase_times = <0x00>;
					input_booster,tail_times = <0x2bc>;
					input_booster,type = <0x09>;
				};

				booster_key@2 {
					input_booster,cpu_freqs = <0x1174c0>;
					input_booster,dma_latency = <0x00>;
					input_booster,head_times = <0x00>;
					input_booster,hmp_boost = <0x01>;
					input_booster,int_freqs = <0x00>;
					input_booster,kfc_freqs = <0x00>;
					input_booster,label = "TOUCHKEY";
					input_booster,levels = <0x01>;
					input_booster,mif_freqs = <0x00>;
					input_booster,phase_times = <0x00>;
					input_booster,tail_times = <0xc8>;
					input_booster,type = <0x01>;
				};

				booster_key@3 {
					input_booster,cpu_freqs = <0x1174c0 0x1174c0 0xe4840>;
					input_booster,dma_latency = <0x00 0x00 0x00>;
					input_booster,head_times = <0x82 0x82 0x00>;
					input_booster,hmp_boost = <0x01 0x01 0x01>;
					input_booster,int_freqs = <0x00 0x00 0x00>;
					input_booster,kfc_freqs = <0xc4c70 0xc4c70 0xc4c70>;
					input_booster,label = "TOUCH";
					input_booster,levels = <0x01 0x02 0x03>;
					input_booster,mif_freqs = <0xf78f0 0xf78f0 0xf78f0>;
					input_booster,phase_times = <0x00 0x00 0x00>;
					input_booster,tail_times = <0x00 0x00 0x1f4>;
					input_booster,type = <0x02>;
				};

				booster_key@4 {
					input_booster,cpu_freqs = <0x1174c0 0xe4840>;
					input_booster,dma_latency = <0x00 0x00>;
					input_booster,head_times = <0x3e8 0x00>;
					input_booster,hmp_boost = <0x01 0x01>;
					input_booster,int_freqs = <0x00 0x00>;
					input_booster,kfc_freqs = <0xc4c70 0xc4c70>;
					input_booster,label = "MULTITOUCH";
					input_booster,levels = <0x01 0x02>;
					input_booster,mif_freqs = <0xf78f0 0xf78f0>;
					input_booster,phase_times = <0x00 0x00>;
					input_booster,tail_times = <0x00 0x1f4>;
					input_booster,type = <0x03>;
				};

				booster_key@5 {
					input_booster,cpu_freqs = <0x1174c0 0x1174c0>;
					input_booster,dma_latency = <0x00 0x00>;
					input_booster,head_times = <0x82 0x82>;
					input_booster,hmp_boost = <0x01 0x01>;
					input_booster,int_freqs = <0x00 0x00>;
					input_booster,kfc_freqs = <0xc4c70 0xc4c70>;
					input_booster,label = "KEYBOARD";
					input_booster,levels = <0x01 0x02>;
					input_booster,mif_freqs = <0x00 0x00>;
					input_booster,phase_times = <0x00 0x00>;
					input_booster,tail_times = <0x00 0x00>;
					input_booster,type = <0x04>;
				};

				booster_key@6 {
					input_booster,cpu_freqs = <0x1174c0 0xe4840>;
					input_booster,dma_latency = <0x00 0x00>;
					input_booster,head_times = <0x82 0x00>;
					input_booster,hmp_boost = <0x01 0x01>;
					input_booster,int_freqs = <0x00 0x00>;
					input_booster,kfc_freqs = <0xc4c70 0xc4c70>;
					input_booster,label = "MOUSE";
					input_booster,levels = <0x01 0x02>;
					input_booster,mif_freqs = <0x00 0x00>;
					input_booster,phase_times = <0x00 0x00>;
					input_booster,tail_times = <0x00 0x1f4>;
					input_booster,type = <0x05>;
				};

				booster_key@7 {
					input_booster,cpu_freqs = <0x1174c0 0x00>;
					input_booster,dma_latency = <0x00 0x00>;
					input_booster,head_times = <0x82 0x00>;
					input_booster,hmp_boost = <0x01 0x00>;
					input_booster,int_freqs = <0x00 0x00>;
					input_booster,kfc_freqs = <0xc4c70 0x00>;
					input_booster,label = "MOUSE WHEEL";
					input_booster,levels = <0x01 0x02>;
					input_booster,mif_freqs = <0x00 0x00>;
					input_booster,phase_times = <0x00 0x00>;
					input_booster,tail_times = <0x00 0x00>;
					input_booster,type = <0x06>;
				};

				booster_key@8 {
					input_booster,cpu_freqs = <0x1174c0 0xe4840>;
					input_booster,dma_latency = <0x00 0x00>;
					input_booster,head_times = <0x82 0x00>;
					input_booster,hmp_boost = <0x01 0x01>;
					input_booster,int_freqs = <0x00 0x00>;
					input_booster,kfc_freqs = <0xc4c70 0xc4c70>;
					input_booster,label = "PEN HOVER";
					input_booster,levels = <0x01 0x02>;
					input_booster,mif_freqs = <0x00 0x00>;
					input_booster,phase_times = <0x00 0x00>;
					input_booster,tail_times = <0x00 0x1f4>;
					input_booster,type = <0x07>;
				};

				booster_key@9 {
					input_booster,bimc_freqs = <0x00 0x00>;
					input_booster,cpu_freqs = <0x1fbd00 0xe4840>;
					input_booster,dma_latency = <0x00 0x00>;
					input_booster,head_times = <0x82 0x00>;
					input_booster,hmp_boost = <0x01 0x01>;
					input_booster,kfc_freqs = <0x1a94b0 0xc4c70>;
					input_booster,label = "PEN";
					input_booster,levels = <0x01 0x02>;
					input_booster,tail_times = <0x00 0x258>;
					input_booster,type = <0x08>;
				};
			};
		};
	};

	fragment@lcd {
		target-path = "/";

		__overlay__ {

			decon_board_ea8076 {
				gpio_con = <0xffffffff 0x07 0x00>;
				gpio_det = <0xffffffff 0x01 0x01>;
				gpio_err = <0xffffffff 0x01 0x01>;
				gpio_lcd_en_1p8 = <0xffffffff 0x02 0x00>;
				gpio_lcd_en_3p0 = <0xffffffff 0x04 0x00>;
				gpio_lcd_rst = <0xffffffff 0x03 0x00>;
				gpio_pcd = <0xffffffff 0x05 0x01>;
				linux,phandle = <0x01>;
				phandle = <0x01>;

				dsim_reset_panel {
					type = "gpio,high\0gpio_lcd_rst\0delay,usleep\01000\0gpio,low\0gpio_lcd_rst\0delay,usleep\01000\0gpio,high\0gpio_lcd_rst\0delay,usleep\010000";
				};

				dsim_set_panel_power_disable {
					type = "gpio,low\0gpio_lcd_rst\0delay,usleep\010000\0gpio,low\0gpio_lcd_en_1p8\0delay,usleep\05000\0gpio,low\0gpio_lcd_en_3p0\0delay,usleep\05000";
				};

				dsim_set_panel_power_enable {
					type = "gpio,high\0gpio_lcd_en_1p8\0delay,usleep\01000\0gpio,high\0gpio_lcd_en_3p0\0delay,usleep\010000";
				};
			};

			ea8076 {
				cmd_underrun_lp_ref = <0x75e>;
				data_lane = <0x04>;
				decon_board = <0x01>;
				dsc_cnt = <0x00>;
				dsc_en = <0x00>;
				dsc_slice_num = <0x00>;
				hdr_max_avg_luma = <0x124f80>;
				hdr_max_luma = "\0=\t";
				hdr_min_luma = <0x05>;
				hdr_num = <0x01>;
				hdr_type = <0x02 0x00 0x00 0x00>;
				linux,phandle = <0x02>;
				mic_en = <0x00>;
				mic_ratio = <0x00>;
				mic_ver = <0x00>;
				mode = <0x02>;
				mres_en = <0x00>;
				noncontinuous_clklane = <0x01>;
				phandle = <0x02>;
				resolution = <0x438 0x960>;
				size = <0x43 0x96>;
				timing,dsi-escape-clk = <0x10>;
				timing,dsi-hs-clk = <0x4b0>;
				timing,h-porch = <0x02 0x02 0x02>;
				timing,pmsk = <0x03 0x115 0x01 0x00>;
				timing,refresh = <0x3c>;
				timing,v-porch = <0x10 0xb0 0x01>;
				type_of_ddi = <0x01>;
				update_min = <0x438 0x02>;
			};
		};
	};

	fragment@model {
		target-path = "/";

		__overlay__ {
			#address-cells = <0x02>;
			#size-cells = <0x01>;
			model = "Samsung M31S EUR OPEN REV00 board based on Exynos9611";

			abc_hub {
				compatible = "samsung,abc_hub";
				status = "okay";

				bootc {
					bootc,time_spec_eng = <0x186a0>;
					bootc,time_spec_fac = <0x186a0>;
					bootc,time_spec_user = <0x186a0>;
				};
			};

			argos {
				#address-cells = <0x01>;
				compatible = "samsung,argos";

				boot_device@1 {
					net_boost,label = "IPC";
					net_boost,node = "rmnet0 rmnet1 rmnet2 rmnet3 rmnet4 rmnet5 rmnet6 rmnet7 umts_dm0";

					net_boost,table {

						level_0 {
							lit_min = <0xde2b0>;
							mif = <0xce4c8>;
							threshold = <0x32>;
						};

						level_1 {
							lit_min = <0x143bb0>;
							mif = <0xf78f0>;
							threshold = <0x64>;
						};

						level_2 {
							lit_min = <0x176830>;
							mif = <0x14a140>;
							threshold = <0xc8>;
						};

						level_3 {
							big_min = <0x196400>;
							lit_min = <0x163780>;
							mif = <0x177bb8>;
							threshold = <0x12c>;
						};
					};
				};

				boot_device@2 {
					net_boost,label = "CLAT";
					net_boost,node = "clat clat4 v4-rmnet0 v4-rmnet1 v4-rmnet2 v4-rmnet3 v4-rmnet4 v4-rmnet5 v4-rmnet6 v4-rmnet7";

					net_boost,table {

						level_0 {
							big_min = <0xfde80>;
							mif = <0xf78f0>;
							threshold = <0x64>;
						};

						level_1 {
							big_min = <0x130b00>;
							mif = <0x14a140>;
							threshold = <0x96>;
						};

						level_2 {
							big_min = <0x163780>;
							mif = <0x1fefc8>;
							threshold = <0xc8>;
						};
					};
				};

				boot_device@3 {
					net_boost,label = "USB";
					net_boost,node = "rndis0";

					net_boost,table {

						level_0 {
							irq_affinity = "enable";
							threshold = <0x00>;
						};
					};
				};

				boot_device@4 {
					net_boost,label = "WIFI TX";
					net_boost,node = "wlan0";

					net_boost,table {

						level_0 {
							big_min = <0x1e26c0>;
							lit_min = <0x143bb0>;
							mif = <0xf78f0>;
							threshold = <0x64>;
						};

						level_1 {
							big_min = <0x215340>;
							lit_min = <0x176830>;
							mif = <0x14a140>;
							threshold = <0xc8>;
						};
					};
				};
			};

			dwmmc2@13550000 {
				#address-cells = <0x01>;
				#size-cells = <0x00>;
				bypass-for-allpass;
				card-detect = <0xffffffff 0x04 0x0f>;
				card-detect-delay = <0xc8>;
				card-detect-gpio;
				card-init-hwacg-ctrl;
				ciu_clkin = <0x19 0x32 0x32 0x19 0x32 0x64 0xc8 0x32 0x32>;
				clk-drive-number = <0x04>;
				clock-frequency = <0x2faf0800>;
				data-timeout = <0xc8>;
				desc-size = <0x04>;
				fifo-depth = <0x40>;
				hto-timeout = <0x50>;
				num-ref-clks = <0x09>;
				num-slots = <0x01>;
				pinctrl-0 = <0xffffffff 0xffffffff 0xffffffff 0xffffffff 0x13>;
				pinctrl-1 = <0xffffffff>;
				pinctrl-2 = <0xffffffff>;
				pinctrl-3 = <0xffffffff>;
				pinctrl-4 = <0xffffffff>;
				pinctrl-names = "default\0fast-slew-rate-1x\0fast-slew-rate-2x\0fast-slew-rate-3x\0fast-slew-rate-4x";
				qos-dvfs-int-level = <0x82208>;
				qos-dvfs-mif-level = <0xa50a0>;
				samsung,dw-mshc-ciu-div = <0x03>;
				samsung,dw-mshc-ddr-timing = <0x03 0x00 0x02 0x01>;
				samsung,dw-mshc-sdr-timing = <0x03 0x00 0x02 0x00>;
				samsung,dw-mshc-sdr104-timing = <0x03 0x00 0x03 0x00>;
				samsung,dw-mshc-sdr50-timing = <0x03 0x00 0x04 0x02>;
				sd-uhs-sdr104;
				sd-uhs-sdr50;
				sec-sd-slot-type = <0x02>;
				skip-init-mmc-scan;
				ssc-rate = <0x03>;
				status = "okay";
				supports-4bit;
				supports-cmd23;
				supports-erase;
				supports-highspeed;

				slot@0 {
					bus-width = <0x04>;
					disable-wp;
					reg = <0x00>;
				};
			};

			exynos_rgt {
				compatible = "samsung,exynos-rgt";
			};

			fixed-rate-clocks {

				oscclk {
					clock-frequency = <0x18cba80>;
					compatible = "samsung,exynos9610-oscclk";
				};
			};

			fixedregulator@1 {
				compatible = "regulator-fixed";
				linux,phandle = <0x65>;
				phandle = <0x65>;
				regulator-always-on;
				regulator-boot-on;
				regulator-max-microvolt = <0x401640>;
				regulator-min-microvolt = <0x401640>;
				regulator-name = "V_SYS";
			};

			gnss_pdata {
				compatible = "samsung,gnss_shdmem_if";
				fault_info = <0x01 0x200000 0x180000>;
				interrupt-names = "ACTIVE\0WATCHDOG\0WAKEUP\0REQ_INIT";
				interrupts = <0x00 0x1b 0x00 0x00 0x51 0x00 0x00 0x50 0x00 0x00 0x4f 0x00>;
				mbox_info = <0x0d>;
				mbx,int_ap2gnss_ack_wake_clr = <0x04>;
				mbx,int_ap2gnss_ack_wake_set = <0x03>;
				mbx,int_ap2gnss_bcmd = <0x00>;
				mbx,int_ap2gnss_ipc_msg = <0x02>;
				mbx,int_ap2gnss_req_fault_info = <0x01>;
				mbx,irq_gnss2ap_bcmd = <0x00>;
				mbx,irq_gnss2ap_ipc_msg = <0x02>;
				mbx,irq_gnss2ap_req_wake_clr = <0x04>;
				mbx,irq_gnss2ap_rsp_fault_info = <0x01>;
				mbx,reg_bcmd_ctrl = <0x00 0x01 0x02 0x03>;
				memory-region = <0xffffffff>;
				reg_rx_head = <0x01 0x03>;
				reg_rx_ipc_msg = <0x01 0x05>;
				reg_rx_tail = <0x01 0x02>;
				reg_tx_head = <0x01 0x01>;
				reg_tx_ipc_msg = <0x01 0x04>;
				reg_tx_tail = <0x01 0x00>;
				shmem,device_node_name = "gnss_ipc";
				shmem,ipc_offset = <0x380000>;
				shmem,ipc_reg_cnt = <0x20>;
				shmem,ipc_size = <0x80000>;
				shmem,name = "KEPLER";
				status = "okay";
			};

			gpio_keys {
				#address-cells = <0x01>;
				#size-cells = <0x00>;
				compatible = "gpio-keys";
				pinctrl-0 = <0x0e 0x0f 0x10>;
				pinctrl-names = "default";
				status = "okay";

				button@2 {
					gpios = <0xffffffff 0x06 0x0f>;
					label = "gpio-keys: KEY_VOLUMEDOWN";
					linux,code = <0x72>;
				};

				button@3 {
					gpios = <0xffffffff 0x05 0x0f>;
					label = "gpio-keys: KEY_VOLUMEUP";
					linux,code = <0x73>;
				};

				button@4 {
					gpio-key,wakeup = <0x01>;
					gpios = <0xffffffff 0x07 0x0f>;
					label = "gpio-keys: KEY_POWER";
					linux,code = <0x74>;
				};
			};

			i2c@13870000 {
				#address-cells = <0x01>;
				#size-cells = <0x00>;
				linux,phandle = <0x64>;
				phandle = <0x64>;
				samsung,i2c-max-bus-freq = <0x61a80>;
				samsung,i2c-sda-delay = <0x64>;
				status = "okay";

				mms_ts@48 {
					compatible = "melfas,mms_ts";
					enable_settings_aot;
					melfas,area-size = <0x85 0x10a 0x155>;
					melfas,display_resolution = <0x438 0x960>;
					melfas,event_info = <0x0a 0x10 0x01>;
					melfas,fw_name = "tsp_melfas/mss100_m31s.fw";
					melfas,irq-gpio = <0xffffffff 0x00 0x00>;
					melfas,max_x_y = <0xfff 0xfff>;
					melfas,node_info = <0x10 0x22 0x00>;
					melfas,regulator_boot_on;
					melfas,scl-gpio = <0xffffffff 0x01 0x00>;
					melfas,sda-gpio = <0xffffffff 0x00 0x00>;
					melfas,support_lpm = "true";
					melfas,support_protos;
					melfas,vdd_en = "tsp_ldo_en";
					pinctrl-0 = <0x11>;
					pinctrl-1 = <0x12>;
					pinctrl-names = "on_state\0off_state";
					reg = <0x48>;
					support_ear_detect_mode;
					support_open_short_test;
				};
			};

			mcu_ipc@11920000 {
				compatible = "samsung,exynos-shd-ipc-mailbox";
				interrupts = <0x00 0x28 0x00>;
				linux,phandle = <0x63>;
				mcu,id = <0x00>;
				mcu,irq_affinity_mask = <0x03>;
				mcu,name = "mcu_ipc_cp";
				phandle = <0x63>;
				reg = <0x00 0x11920000 0x180>;
			};

			mcu_ipc@11A00000 {
				compatible = "samsung,exynos-shd-ipc-mailbox";
				interrupts = <0x00 0x2b 0x00>;
				linux,phandle = <0x0d>;
				mcu,id = <0x01>;
				mcu,name = "mcu_ipc_gnss";
				phandle = <0x0d>;
				reg = <0x00 0x11a00000 0x180>;
			};

			mif_pdata {
				gpios = <0xffffffff 0x02 0x00 0xffffffff 0x03 0x00 0xffffffff 0x04 0x00 0xffffffff 0x05 0x00>;
				pinctrl-names = "default";
			};

			nad_balancer {
				compatible = "samsung,sec_nad_balancer";
				nad_balancer,timeout = <0x190>;
				status = "okay";

				qos {

					cl0 {
						qos,delay_time = <0x0a>;
						qos,label = "LIT";
						qos,table = <0x1a94b0 0x18fe70 0x176830 0x163780 0x143bb0 0x12a570 0x110f30 0x101148 0xde2b0 0xc4c70 0xab630 0x91ff0 0x62638>;
						qos,table_size = <0x0d>;
					};

					cl1 {
						qos,delay_time = <0x0a>;
						qos,label = "BIG";
						qos,table = <0x234f10 0x21b8d0 0x215340 0x1fbd00 0x1e26c0 0x1cf610 0x1afa40 0x196400 0x1702a0 0x163780 0x14a140 0x130b00 0x1174c0 0xfde80 0xe4840>;
						qos,table_size = <0x0f>;
					};

					mif {
						qos,delay_time = <0x0a>;
						qos,label = "MIF";
						qos,table = <0x1fefc8 0x1e8c50 0x1b5fd0 0x177bb8 0xcbbc40 0xf78f0 0xce4c8 0xa50a0 0x854d0 0x664b8>;
						qos,table_size = <0x0a>;
					};
				};

				sleep {
					sleep,resume_threshold = <0x3e8>;
					sleep,suspend_threshold = <0x3e8>;
				};
			};

			sec_abc {
				compatible = "samsung,sec_abc";
				status = "okay";

				aicl {
					aicl,label = "battery aicl";
					aicl,threshold_count = <0x05>;
					aicl,threshold_time = <0x12c>;
				};

				gpu {
					gpu,label = "GPU fault";
					gpu,threshold_count = <0x14>;
					gpu,threshold_time = <0x4b0>;
				};
			};

			sec_detect_conn {
				compatible = "samsung,sec_detect_conn";
				pinctrl-0 = <0x14>;
				pinctrl-names = "default";
				sec,det_conn_gpios = <0xffffffff 0x02 0x00>;
				sec,det_conn_irq_type = <0x03>;
				sec,det_conn_name = "SUB_CONNECT";
			};

			sec_thermistor@0 {
				adc_array = <0x116 0x182 0x225 0x27f 0x2f7 0x374 0x405 0x4a7 0x560 0x60f 0x6f3 0x7b8 0x8a9 0x987 0xa50 0xb11 0xbc4 0xc60 0xcdb 0xd45 0xd94>;
				compatible = "samsung,sec-thermistor";
				id = <0x00>;
				io-channel-names = "adc-ap-temp";
				io-channel-ranges;
				io-channels = <0xffffffff 0x00>;
				status = "okay";
				temp_array = <0x384 0x320 0x2bc 0x28a 0x258 0x226 0x1f4 0x1c2 0x190 0x15e 0x12c 0xfa 0xc8 0x96 0x64 0x32 0x00 0xffffffce 0xffffff9c 0xffffff6a 0xffffff38>;
				thermistor_name = "sec-ap-thermistor";
			};

			sec_thermistor@6 {
				adc_array = <0x11a 0x18c 0x22d 0x28d 0x306 0x382 0x416 0x4b6 0x56d 0x629 0x705 0x7d7 0x8c0 0x9a1 0xa6d 0xb30 0xbe1 0xc79 0xcf9 0xd62 0xdb5>;
				compatible = "samsung,sec-thermistor";
				id = <0x01>;
				io-channel-names = "adc-wf-temp";
				io-channel-ranges;
				io-channels = <0xffffffff 0x06>;
				status = "okay";
				temp_array = <0x384 0x320 0x2bc 0x28a 0x258 0x226 0x1f4 0x1c2 0x190 0x15e 0x12c 0xfa 0xc8 0x96 0x64 0x32 0x00 0xffffffce 0xffffff9c 0xffffff6a 0xffffff38>;
				thermistor_name = "sec-wf-thermistor";
			};

			secgpio_dvs {
				compatible = "samsung,exynos9610-secgpio-dvs";
				status = "okay";
			};

			speedy@11a10000 {
				#address-cells = <0x01>;
				#size-cells = <0x00>;
				status = "okay";

				s2mpu09mfd@00 {
					acpm-ipc-channel = <0x02>;
					check_jigon = <0x00>;
					compatible = "samsung,s2mpu09mfd";
					i2c-speedy-address;
					init_time,hour = <0x0c>;
					init_time,mday = <0x01>;
					init_time,min = <0x00>;
					init_time,mon = <0x00>;
					init_time,sec = <0x00>;
					init_time,wday = <0x03>;
					init_time,year = <0x78>;
					interrupt-parent = <0xffffffff>;
					interrupts = <0x02 0x00 0x00>;
					pinctrl-0 = <0x0b 0x0c>;
					pinctrl-names = "default";
					reg = <0x00>;
					s2mpu09,irq-gpio = <0xffffffff 0x00 0x00>;
					s2mpu09,wakeup = "enabled";
					smpl_en = "enabled";
					smpl_timer_val = <0x00>;
					wtsr_en = "enabled";
					wtsr_timer_val = <0x03>;

					regulators {

						BUCK1 {
							linux,phandle = <0x42>;
							phandle = <0x42>;
							regulator-always-on;
							regulator-initial-mode = <0x02>;
							regulator-max-microvolt = <0x10c8e0>;
							regulator-min-microvolt = <0x7a120>;
							regulator-name = "vdd_mif";
							regulator-ramp-delay = <0x2ee0>;
						};

						BUCK2 {
							linux,phandle = <0x43>;
							phandle = <0x43>;
							regulator-always-on;
							regulator-initial-mode = <0x01>;
							regulator-max-microvolt = <0x13d620>;
							regulator-min-microvolt = <0x7a120>;
							regulator-name = "vdd_cpucl1";
							regulator-ramp-delay = <0x2ee0>;
						};

						BUCK3 {
							linux,phandle = <0x44>;
							phandle = <0x44>;
							regulator-always-on;
							regulator-initial-mode = <0x01>;
							regulator-max-microvolt = <0x13d620>;
							regulator-min-microvolt = <0x7a120>;
							regulator-name = "vdd_cpucl0";
							regulator-ramp-delay = <0x2ee0>;
						};

						BUCK4 {
							linux,phandle = <0x45>;
							phandle = <0x45>;
							regulator-always-on;
							regulator-initial-mode = <0x02>;
							regulator-max-microvolt = <0x10c8e0>;
							regulator-min-microvolt = <0x7a120>;
							regulator-name = "vdd_int";
							regulator-ramp-delay = <0x2ee0>;
						};

						BUCK5 {
							linux,phandle = <0x46>;
							phandle = <0x46>;
							regulator-always-on;
							regulator-initial-mode = <0x02>;
							regulator-max-microvolt = <0x124f80>;
							regulator-min-microvolt = <0x7a120>;
							regulator-name = "vdd_g3d";
							regulator-ramp-delay = <0x2ee0>;
						};

						BUCK6 {
							linux,phandle = <0x47>;
							phandle = <0x47>;
							regulator-always-on;
							regulator-initial-mode = <0x02>;
							regulator-max-microvolt = <0x13d620>;
							regulator-min-microvolt = <0x7a120>;
							regulator-name = "vdd_cam_vipx";
							regulator-ramp-delay = <0x2ee0>;
						};

						BUCK7 {
							linux,phandle = <0x48>;
							phandle = <0x48>;
							regulator-always-on;
							regulator-initial-mode = <0x03>;
							regulator-max-microvolt = <0x13d620>;
							regulator-min-microvolt = <0x7a120>;
							regulator-name = "vdd2_mem";
							regulator-ramp-delay = <0x2ee0>;
						};

						BUCK8 {
							linux,phandle = <0x49>;
							phandle = <0x49>;
							regulator-always-on;
							regulator-initial-mode = <0x03>;
							regulator-max-microvolt = <0x16e360>;
							regulator-min-microvolt = <0x124f80>;
							regulator-name = "vdd_lldo";
							regulator-ramp-delay = <0x2ee0>;
						};

						BUCK9 {
							linux,phandle = <0x4a>;
							phandle = <0x4a>;
							regulator-always-on;
							regulator-initial-mode = <0x03>;
							regulator-max-microvolt = <0x200b20>;
							regulator-min-microvolt = <0x1b7740>;
							regulator-name = "vdd_mldo";
							regulator-ramp-delay = <0x2ee0>;
						};

						LDO1 {
							linux,phandle = <0x4b>;
							phandle = <0x4b>;
							regulator-always-on;
							regulator-initial-mode = <0x03>;
							regulator-max-microvolt = <0x13d620>;
							regulator-min-microvolt = <0xaae60>;
							regulator-name = "vdd_ldo1";
							regulator-ramp-delay = <0x2ee0>;
						};

						LDO10 {
							linux,phandle = <0x54>;
							phandle = <0x54>;
							regulator-always-on;
							regulator-initial-mode = <0x01>;
							regulator-max-microvolt = <0x13d620>;
							regulator-min-microvolt = <0x7a120>;
							regulator-name = "vdd_ldo10";
							regulator-ramp-delay = <0x2ee0>;
						};

						LDO11 {
							linux,phandle = <0x55>;
							phandle = <0x55>;
							regulator-always-on;
							regulator-initial-mode = <0x03>;
							regulator-max-microvolt = <0x13d620>;
							regulator-min-microvolt = <0x7a120>;
							regulator-name = "vdd_ldo11";
							regulator-ramp-delay = <0x2ee0>;
						};

						LDO12 {
							linux,phandle = <0x56>;
							phandle = <0x56>;
							regulator-initial-mode = <0x03>;
							regulator-max-microvolt = <0x13d620>;
							regulator-min-microvolt = "\0\f5";
							regulator-name = "vdd_ldo12";
							regulator-ramp-delay = <0x2ee0>;
						};

						LDO13 {
							linux,phandle = <0x57>;
							phandle = <0x57>;
							regulator-initial-mode = <0x03>;
							regulator-max-microvolt = <0x1dc130>;
							regulator-min-microvolt = "\0\f5";
							regulator-name = "vdd_ldo13";
							regulator-ramp-delay = <0x2ee0>;
						};

						LDO14 {
							linux,phandle = <0x58>;
							phandle = <0x58>;
							regulator-initial-mode = <0x03>;
							regulator-max-microvolt = <0x337f98>;
							regulator-min-microvolt = <0x1b7740>;
							regulator-name = "vdd_ldo14";
							regulator-ramp-delay = <0x2ee0>;
						};

						LDO2 {
							linux,phandle = <0x4c>;
							phandle = <0x4c>;
							regulator-max-microvolt = <0x2d0370>;
							regulator-min-microvolt = <0x1b7740>;
							regulator-name = "vqmmc";
							regulator-ramp-delay = <0x2ee0>;
						};

						LDO3 {
							linux,phandle = <0x4d>;
							phandle = <0x4d>;
							regulator-always-on;
							regulator-initial-mode = <0x03>;
							regulator-max-microvolt = <0x1dc130>;
							regulator-min-microvolt = "\0\f5";
							regulator-name = "vdd_ldo3";
							regulator-ramp-delay = <0x2ee0>;
						};

						LDO33 {
							linux,phandle = <0x59>;
							phandle = <0x59>;
							regulator-max-microvolt = <0x1b7740>;
							regulator-min-microvolt = <0x1b7740>;
							regulator-name = "vdd_ldo33";
							regulator-ramp-delay = <0x2ee0>;
						};

						LDO34 {
							linux,phandle = <0x5a>;
							phandle = <0x5a>;
							regulator-max-microvolt = <0x337f98>;
							regulator-min-microvolt = <0x1b7740>;
							regulator-name = "vdd_ldo34";
							regulator-ramp-delay = <0x2ee0>;
						};

						LDO35 {
							linux,phandle = <0x5b>;
							phandle = <0x5b>;
							regulator-max-microvolt = <0x2d0370>;
							regulator-min-microvolt = <0x1b7740>;
							regulator-name = "vmmc";
							regulator-ramp-delay = <0x2ee0>;
						};

						LDO36 {
							linux,phandle = <0x5c>;
							phandle = <0x5c>;
							regulator-always-on;
							regulator-initial-mode = <0x01>;
							regulator-max-microvolt = <0x13d620>;
							regulator-min-microvolt = <0x7a120>;
							regulator-name = "vdd_ldo36";
							regulator-ramp-delay = <0x2ee0>;
						};

						LDO37 {
							linux,phandle = <0x5d>;
							phandle = <0x5d>;
							regulator-max-microvolt = <0x2ab980>;
							regulator-min-microvolt = <0x2ab980>;
							regulator-name = "vdd_ldo37";
							regulator-ramp-delay = <0x2ee0>;
						};

						LDO38 {
							linux,phandle = <0x5e>;
							phandle = <0x5e>;
							regulator-max-microvolt = <0x325aa0>;
							regulator-min-microvolt = <0x325aa0>;
							regulator-name = "VDD_BTP_3P3";
							regulator-ramp-delay = <0x2ee0>;
						};

						LDO39 {
							linux,phandle = <0x5f>;
							phandle = <0x5f>;
							regulator-initial-mode = <0x03>;
							regulator-max-microvolt = <0x1b7740>;
							regulator-min-microvolt = <0x1b7740>;
							regulator-name = "VDD_NFC_1P8";
							regulator-ramp-delay = <0x2ee0>;
						};

						LDO4 {
							linux,phandle = <0x4e>;
							phandle = <0x4e>;
							regulator-always-on;
							regulator-initial-mode = <0x01>;
							regulator-max-microvolt = <0x10c8e0>;
							regulator-min-microvolt = <0x7a120>;
							regulator-name = "vdd_ldo4";
							regulator-ramp-delay = <0x2ee0>;
						};

						LDO40 {
							linux,phandle = <0x08>;
							phandle = <0x08>;
							regulator-boot-on;
							regulator-initial-mode = <0x03>;
							regulator-max-microvolt = <0x325aa0>;
							regulator-min-microvolt = <0x325aa0>;
							regulator-name = "regulator_3v3";
						};

						LDO41 {
							linux,phandle = <0x60>;
							phandle = <0x60>;
							regulator-always-on;
							regulator-max-microvolt = <0x325aa0>;
							regulator-min-microvolt = <0x325aa0>;
							regulator-name = "VDD_GRIP_3P3";
							regulator-ramp-delay = <0x2ee0>;
						};

						LDO42 {
							linux,phandle = <0x07>;
							phandle = <0x07>;
							regulator-boot-on;
							regulator-initial-mode = <0x03>;
							regulator-max-microvolt = <0x1b7740>;
							regulator-min-microvolt = <0x1b7740>;
							regulator-name = "regulator_1v8";
							regulator-ramp-delay = <0x2ee0>;
						};

						LDO43 {
							linux,phandle = <0x61>;
							phandle = <0x61>;
							regulator-always-on;
							regulator-initial-mode = <0x01>;
							regulator-max-microvolt = <0x13d620>;
							regulator-min-microvolt = <0x7a120>;
							regulator-name = "vdd_ldo43";
							regulator-ramp-delay = <0x2ee0>;
						};

						LDO44 {
							linux,phandle = <0x62>;
							phandle = <0x62>;
							regulator-max-microvolt = <0x100590>;
							regulator-min-microvolt = <0x100590>;
							regulator-name = "vdd_ldo44";
							regulator-ramp-delay = <0x2ee0>;
						};

						LDO5 {
							linux,phandle = <0x4f>;
							phandle = <0x4f>;
							regulator-always-on;
							regulator-initial-mode = <0x01>;
							regulator-max-microvolt = <0x13d620>;
							regulator-min-microvolt = "\0\f5";
							regulator-name = "vdd_ldo5";
							regulator-ramp-delay = <0x2ee0>;
						};

						LDO6 {
							linux,phandle = <0x50>;
							phandle = <0x50>;
							regulator-always-on;
							regulator-initial-mode = <0x01>;
							regulator-max-microvolt = <0x13d620>;
							regulator-min-microvolt = "\0\f5";
							regulator-name = "vdd_ldo6";
							regulator-ramp-delay = <0x2ee0>;
						};

						LDO7 {
							linux,phandle = <0x51>;
							phandle = <0x51>;
							regulator-always-on;
							regulator-initial-mode = <0x01>;
							regulator-max-microvolt = <0x1dc130>;
							regulator-min-microvolt = "\0\f5";
							regulator-name = "vdd_ldo7";
							regulator-ramp-delay = <0x2ee0>;
						};

						LDO8 {
							linux,phandle = <0x52>;
							phandle = <0x52>;
							regulator-always-on;
							regulator-initial-mode = <0x01>;
							regulator-max-microvolt = <0x13d620>;
							regulator-min-microvolt = <0x7a120>;
							regulator-name = "vdd_ldo8";
							regulator-ramp-delay = <0x2ee0>;
						};

						LDO9 {
							linux,phandle = <0x53>;
							phandle = <0x53>;
							regulator-always-on;
							regulator-initial-mode = <0x01>;
							regulator-max-microvolt = <0x13d620>;
							regulator-min-microvolt = <0x7a120>;
							regulator-name = "vdd_ldo9";
							regulator-ramp-delay = <0x2ee0>;
						};
					};
				};
			};

			tsp_ldo_en {
				compatible = "regulator-fixed";
				enable-active-high;
				gpio = <0xffffffff 0x01 0x00>;
				regulator-boot-on;
				regulator-max-microvolt = <0x2dc6c0>;
				regulator-min-microvolt = <0x2dc6c0>;
				regulator-name = "tsp_ldo_en";
			};

			ufs-srpmb {
				compatible = "samsung,ufs-srpmb";
				interrupts = <0x00 0x1cc 0x00>;
			};

			usb3_hs_tune {
				hs_tune_cnt = <0x0a>;
				linux,phandle = <0x16>;
				phandle = <0x16>;

				hs_tune1 {
					tune_name = "tx_pre_emp";
					tune_value = <0x03 0x03>;
				};

				hs_tune10 {
					tune_name = "utim_clk";
					tune_value = <0x01 0x01>;
				};

				hs_tune2 {
					tune_name = "tx_pre_emp_plus";
					tune_value = <0x00 0x00>;
				};

				hs_tune3 {
					tune_name = "tx_vref";
					tune_value = <0x07 0x07>;
				};

				hs_tune4 {
					tune_name = "rx_sqrx";
					tune_value = <0x07 0x07>;
				};

				hs_tune5 {
					tune_name = "tx_rise";
					tune_value = <0x03 0x03>;
				};

				hs_tune6 {
					tune_name = "compdis";
					tune_value = <0x07 0x07>;
				};

				hs_tune7 {
					tune_name = "tx_hsxv";
					tune_value = <0x03 0x03>;
				};

				hs_tune8 {
					tune_name = "tx_fsls";
					tune_value = <0x03 0x03>;
				};

				hs_tune9 {
					tune_name = "tx_res";
					tune_value = <0x03 0x03>;
				};
			};

			usb3_ss_tune {
				linux,phandle = <0x17>;
				phandle = <0x17>;
				ss_tune_cnt = <0x0f>;

				ss_tune1 {
					tune_name = "tx0_term_offset";
					tune_value = <0x00 0x00>;
				};

				ss_tune10 {
					tune_name = "tx_eye_height_cntl_en";
					tune_value = <0x01 0x01>;
				};

				ss_tune11 {
					tune_name = "pipe_tx_deemph_update_delay";
					tune_value = <0x02 0x02>;
				};

				ss_tune12 {
					tune_name = "pcs_tx_swing_full_sstx";
					tune_value = <0x7f 0x7f>;
				};

				ss_tune13 {
					tune_name = "rx_eq_fix_val";
					tune_value = <0x02 0x02>;
				};

				ss_tune14 {
					tune_name = "rx_decode_mode";
					tune_value = <0x01 0x01>;
				};

				ss_tune15 {
					tune_name = "decrese_ss_tx_imp";
					tune_value = <0x01 0x01>;
				};

				ss_tune2 {
					tune_name = "pcs_tx_swing_full";
					tune_value = <0x7f 0x7f>;
				};

				ss_tune3 {
					tune_name = "pcs_tx_deemph_6db";
					tune_value = <0x1c 0x1c>;
				};

				ss_tune4 {
					tune_name = "pcs_tx_deemph_3p5db";
					tune_value = <0x1c 0x1c>;
				};

				ss_tune5 {
					tune_name = "tx_vboost_lvl_sstx";
					tune_value = <0x07 0x07>;
				};

				ss_tune6 {
					tune_name = "tx_vboost_lvl";
					tune_value = <0x04 0x04>;
				};

				ss_tune7 {
					tune_name = "los_level";
					tune_value = <0x09 0x09>;
				};

				ss_tune8 {
					tune_name = "los_bias";
					tune_value = <0x05 0x05>;
				};

				ss_tune9 {
					tune_name = "pcs_rx_los_mask_val";
					tune_value = <0x104 0x104>;
				};
			};

			usb_hs_tune {
				hs_tune_cnt = <0x0c>;
				linux,phandle = <0x15>;
				phandle = <0x15>;

				hs_tune1 {
					tune_name = "tx_vref";
					tune_value = <0x0f 0x0a>;
				};

				hs_tune10 {
					tune_name = "otg";
					tune_value = <0x02 0x02>;
				};

				hs_tune11 {
					tune_name = "enable_user_imp";
					tune_value = <0x00 0x00>;
				};

				hs_tune12 {
					tune_name = "is_phyclock";
					tune_value = <0x01 0x01>;
				};

				hs_tune2 {
					tune_name = "tx_pre_emp";
					tune_value = <0x03 0x03>;
				};

				hs_tune3 {
					tune_name = "tx_pre_emp_plus";
					tune_value = <0x00 0x00>;
				};

				hs_tune4 {
					tune_name = "tx_res";
					tune_value = <0x03 0x03>;
				};

				hs_tune5 {
					tune_name = "tx_rise";
					tune_value = <0x03 0x03>;
				};

				hs_tune6 {
					tune_name = "tx_hsxv";
					tune_value = <0x03 0x03>;
				};

				hs_tune7 {
					tune_name = "tx_fsls";
					tune_value = <0x03 0x03>;
				};

				hs_tune8 {
					tune_name = "rx_sqrx";
					tune_value = <0x07 0x07>;
				};

				hs_tune9 {
					tune_name = "compdis";
					tune_value = <0x07 0x07>;
				};
			};

			usb_notifier {
				compatible = "samsung,usb-notifier";
				disable_host_wakelock;
				udc = <0xffffffff>;
			};
		};
	};

	fragment@modemif {
		target-path = "/";

		__overlay__ {
			#address-cells = <0x02>;
			#size-cells = <0x01>;

			mif_pdata {
				compatible = "sec_modem,modem_pdata";
				interrupts = <0x00 0x4b 0x00>;
				mbx_ap2cp_kerneltime = <0x09>;
				mbx_ap2cp_mif_value = <0x04>;
				mbx_ap2cp_msg = <0x00>;
				mbx_ap2cp_united_status = <0x02>;
				mbx_cp2ap_dvfsreq = <0x04>;
				mbx_cp2ap_dvfsreq_cpu = <0x05>;
				mbx_cp2ap_dvfsreq_int = <0x07>;
				mbx_cp2ap_dvfsreq_mif = <0x06>;
				mbx_cp2ap_msg = <0x01>;
				mbx_cp2ap_pcie_l1ss_disable = <0x11>;
				mbx_cp2ap_united_status = <0x03>;
				mif,int_ap2cp_active = <0x03>;
				mif,int_ap2cp_msg = <0x00>;
				mif,int_ap2cp_status = <0x02>;
				mif,int_ap2cp_uart_noti = <0x0f>;
				mif,int_ap2cp_wakeup = <0x01>;
				mif,ipc_version = <0x32>;
				mif,irq_cp2ap_active = <0x03>;
				mif,irq_cp2ap_msg = <0x00>;
				mif,irq_cp2ap_pcie_l1ss_disable = <0x09>;
				mif,irq_cp2ap_perf_req_cpu = <0x05>;
				mif,irq_cp2ap_perf_req_int = <0x07>;
				mif,irq_cp2ap_perf_req_mif = <0x06>;
				mif,irq_cp2ap_status = <0x02>;
				mif,irq_cp2ap_wakelock = <0x08>;
				mif,link_attrs = <0x7c9>;
				mif,link_name = "shmem";
				mif,link_types = <0x200>;
				mif,modem_net = <0x00>;
				mif,modem_type = <0x0a>;
				mif,name = "s337ap";
				mif,num_iodevs = <0x16>;
				mif,use_handover = <0x00>;
				mif,use_usb_phy = <0x00>;
				reg = <0x00 0x10000 0x00>;
				sbi_ap2cp_kerneltime_sec_mask = <0xfff>;
				sbi_ap2cp_kerneltime_sec_pos = <0x14>;
				sbi_ap2cp_kerneltime_usec_mask = <0xfffff>;
				sbi_ap2cp_kerneltime_usec_pos = <0x00>;
				sbi_ap_status_mask = <0x0f>;
				sbi_ap_status_pos = <0x01>;
				sbi_cp2ap_wakelock_mask = <0x01>;
				sbi_cp2ap_wakelock_pos = <0x06>;
				sbi_cp_evs_mode_mask = <0x01>;
				sbi_cp_evs_mode_pos = <0x07>;
				sbi_cp_rat_mode_mask = <0x3f>;
				sbi_cp_rat_mode_pos = <0x1a>;
				sbi_cp_status_mask = <0x0f>;
				sbi_cp_status_pos = <0x01>;
				sbi_crash_type_mask = <0x0f>;
				sbi_crash_type_pos = <0x19>;
				sbi_device_type_mask = <0x1f>;
				sbi_device_type_pos = <0x14>;
				sbi_ds_det_mask = <0x03>;
				sbi_ds_det_pos = <0x0e>;
				sbi_ext_backtrace_mask = <0x01>;
				sbi_ext_backtrace_pos = <0x11>;
				sbi_lockval_cp2ap_dvfsreq_endian_mask = <0x01>;
				sbi_lockval_cp2ap_dvfsreq_endian_pos = <0x1f>;
				sbi_lockval_cp2ap_dvfsreq_index_mask = <0x7fff>;
				sbi_lockval_cp2ap_dvfsreq_index_pos = <0x00>;
				sbi_lte_active_mask = <0x01>;
				sbi_lte_active_pos = <0x05>;
				sbi_pda_active_mask = <0x01>;
				sbi_pda_active_pos = <0x05>;
				sbi_sys_rev_mask = <0xff>;
				sbi_sys_rev_pos = <0x06>;
				sbi_uart_noti_mask = <0x01>;
				sbi_uart_noti_pos = <0x10>;
				status = "okay";

				iodevs {

					io_device_0 {
						iod,attrs = <0x82>;
						iod,dl_buffer_size = <0x800>;
						iod,dl_num_buffers = <0x10>;
						iod,format = <0x01>;
						iod,id = <0x23>;
						iod,io_type = <0x00>;
						iod,links = <0x200>;
						iod,max_tx_size = <0x800>;
						iod,name = "umts_cass";
						iod,ul_buffer_size = <0x800>;
						iod,ul_num_buffers = <0x10>;
					};

					io_device_1 {
						iod,app = "RIL";
						iod,attrs = <0x82>;
						iod,dl_buffer_size = <0x1000>;
						iod,dl_num_buffers = <0x20>;
						iod,format = <0x00>;
						iod,id = <0xeb>;
						iod,io_type = <0x00>;
						iod,links = <0x200>;
						iod,name = "umts_ipc0";
						iod,ul_buffer_size = <0x1000>;
						iod,ul_num_buffers = <0x10>;
					};

					io_device_10 {
						iod,app = "NET";
						iod,attrs = <0x180>;
						iod,dl_buffer_size = <0x800>;
						iod,dl_num_buffers = <0x00>;
						iod,format = <0x01>;
						iod,id = <0x0d>;
						iod,io_type = <0x01>;
						iod,links = <0x200>;
						iod,name = "rmnet3";
						iod,ul_buffer_size = <0x800>;
						iod,ul_num_buffers = <0x00>;
					};

					io_device_11 {
						iod,attrs = <0x180>;
						iod,dl_buffer_size = <0x800>;
						iod,dl_num_buffers = <0x00>;
						iod,format = <0x01>;
						iod,id = <0x0e>;
						iod,io_type = <0x01>;
						iod,links = <0x200>;
						iod,name = "rmnet4";
						iod,ul_buffer_size = <0x800>;
						iod,ul_num_buffers = <0x00>;
					};

					io_device_12 {
						iod,attrs = <0x180>;
						iod,dl_buffer_size = <0x800>;
						iod,dl_num_buffers = <0x00>;
						iod,format = <0x01>;
						iod,id = <0x0f>;
						iod,io_type = <0x01>;
						iod,links = <0x200>;
						iod,name = "rmnet5";
						iod,ul_buffer_size = <0x800>;
						iod,ul_num_buffers = <0x00>;
					};

					io_device_13 {
						iod,attrs = <0x180>;
						iod,dl_buffer_size = <0x800>;
						iod,dl_num_buffers = <0x00>;
						iod,format = <0x01>;
						iod,id = <0x10>;
						iod,io_type = <0x01>;
						iod,links = <0x200>;
						iod,name = "rmnet6";
						iod,ul_buffer_size = <0x800>;
						iod,ul_num_buffers = <0x00>;
					};

					io_device_14 {
						iod,attrs = <0x180>;
						iod,dl_buffer_size = <0x800>;
						iod,dl_num_buffers = <0x00>;
						iod,format = <0x01>;
						iod,id = <0x11>;
						iod,io_type = <0x01>;
						iod,links = <0x200>;
						iod,name = "rmnet7";
						iod,ul_buffer_size = <0x800>;
						iod,ul_num_buffers = <0x00>;
					};

					io_device_15 {
						iod,app = "RIL";
						iod,attrs = <0x180>;
						iod,dl_buffer_size = <0x800>;
						iod,dl_num_buffers = <0x100>;
						iod,format = <0x03>;
						iod,id = <0x00>;
						iod,io_type = <0x02>;
						iod,links = <0x200>;
						iod,name = "multipdp_hiprio";
						iod,ul_buffer_size = <0x800>;
						iod,ul_num_buffers = <0x100>;
					};

					io_device_16 {
						iod,app = "RIL";
						iod,attrs = <0x180>;
						iod,dl_buffer_size = <0x800>;
						iod,dl_num_buffers = <0x400>;
						iod,format = <0x03>;
						iod,id = <0x00>;
						iod,io_type = <0x02>;
						iod,links = <0x200>;
						iod,name = "multipdp";
						iod,ul_buffer_size = <0x800>;
						iod,ul_num_buffers = <0x200>;
					};

					io_device_17 {
						iod,app = "CBD";
						iod,attrs = <0x02>;
						iod,format = <0x04>;
						iod,id = <0xd7>;
						iod,io_type = <0x00>;
						iod,links = <0x200>;
						iod,name = "umts_boot0";
					};

					io_device_18 {
						iod,app = "CBD";
						iod,attrs = <0x202>;
						iod,format = <0x05>;
						iod,id = <0xe1>;
						iod,io_type = <0x00>;
						iod,links = <0x200>;
						iod,name = "umts_ramdump0";
					};

					io_device_19 {
						iod,app = "VCD";
						iod,attrs = <0x882>;
						iod,dl_buffer_size = <0x800>;
						iod,dl_num_buffers = <0x80>;
						iod,format = <0x01>;
						iod,id = <0x20>;
						iod,io_type = <0x00>;
						iod,links = <0x200>;
						iod,max_tx_size = <0x800>;
						iod,name = "umts_atc0";
						iod,option_region = "usa_vzw";
						iod,ul_buffer_size = <0x800>;
						iod,ul_num_buffers = <0x10>;
					};

					io_device_2 {
						iod,app = "RIL";
						iod,attrs = <0x82>;
						iod,dl_buffer_size = <0x1000>;
						iod,dl_num_buffers = <0x20>;
						iod,format = <0x00>;
						iod,id = <0xec>;
						iod,io_type = <0x00>;
						iod,links = <0x200>;
						iod,name = "umts_ipc1";
						iod,ul_buffer_size = <0x1000>;
						iod,ul_num_buffers = <0x10>;
					};

					io_device_20 {
						iod,attrs = <0x882>;
						iod,dl_buffer_size = <0x800>;
						iod,dl_num_buffers = <0x80>;
						iod,format = <0x01>;
						iod,id = <0x22>;
						iod,io_type = <0x00>;
						iod,links = <0x200>;
						iod,name = "smd4";
						iod,option_region = "usa_";
						iod,ul_buffer_size = <0x800>;
						iod,ul_num_buffers = <0x10>;
					};

					io_device_21 {
						iod,attrs = <0x882>;
						iod,dl_buffer_size = <0x800>;
						iod,dl_num_buffers = <0x80>;
						iod,format = <0x01>;
						iod,id = <0x1a>;
						iod,io_type = <0x00>;
						iod,links = <0x200>;
						iod,name = "umts_ciq0";
						iod,option_region = "usa_";
						iod,ul_buffer_size = <0x800>;
						iod,ul_num_buffers = <0x10>;
					};

					io_device_3 {
						iod,app = "RFS";
						iod,attrs = <0x82>;
						iod,dl_buffer_size = <0x800>;
						iod,dl_num_buffers = <0x200>;
						iod,format = <0x02>;
						iod,id = <0xf5>;
						iod,io_type = <0x00>;
						iod,links = <0x200>;
						iod,name = "umts_rfs0";
						iod,ul_buffer_size = <0x800>;
						iod,ul_num_buffers = <0x10>;
					};

					io_device_4 {
						iod,app = "CSVT";
						iod,attrs = <0x82>;
						iod,dl_buffer_size = <0x800>;
						iod,dl_num_buffers = <0x40>;
						iod,format = <0x01>;
						iod,id = <0x01>;
						iod,io_type = <0x00>;
						iod,links = <0x200>;
						iod,name = "umts_csd";
						iod,ul_buffer_size = <0x800>;
						iod,ul_num_buffers = <0x20>;
					};

					io_device_5 {
						iod,app = "Data Router";
						iod,attrs = <0x82>;
						iod,dl_buffer_size = <0x800>;
						iod,dl_num_buffers = <0x10>;
						iod,format = <0x01>;
						iod,id = <0x19>;
						iod,io_type = <0x00>;
						iod,links = <0x200>;
						iod,max_tx_size = <0x60e>;
						iod,name = "umts_router";
						iod,ul_buffer_size = <0x800>;
						iod,ul_num_buffers = <0x10>;
					};

					io_device_6 {
						iod,app = "DIAG";
						iod,attrs = <0x82>;
						iod,dl_buffer_size = <0x800>;
						iod,dl_num_buffers = <0x80>;
						iod,format = <0x01>;
						iod,id = <0x1c>;
						iod,io_type = <0x00>;
						iod,links = <0x200>;
						iod,name = "umts_dm0";
						iod,ul_buffer_size = <0x800>;
						iod,ul_num_buffers = <0x10>;
					};

					io_device_7 {
						iod,app = "NET";
						iod,attrs = <0x180>;
						iod,dl_buffer_size = <0x800>;
						iod,dl_num_buffers = <0x00>;
						iod,format = <0x01>;
						iod,id = <0x0a>;
						iod,io_type = <0x01>;
						iod,links = <0x200>;
						iod,name = "rmnet0";
						iod,ul_buffer_size = <0x800>;
						iod,ul_num_buffers = <0x00>;
					};

					io_device_8 {
						iod,app = "NET";
						iod,attrs = <0x180>;
						iod,dl_buffer_size = <0x800>;
						iod,dl_num_buffers = <0x00>;
						iod,format = <0x01>;
						iod,id = <0x0b>;
						iod,io_type = <0x01>;
						iod,links = <0x200>;
						iod,name = "rmnet1";
						iod,ul_buffer_size = <0x800>;
						iod,ul_num_buffers = <0x00>;
					};

					io_device_9 {
						iod,app = "NET";
						iod,attrs = <0x180>;
						iod,dl_buffer_size = <0x800>;
						iod,dl_num_buffers = <0x00>;
						iod,format = <0x01>;
						iod,id = <0x0c>;
						iod,io_type = <0x01>;
						iod,links = <0x200>;
						iod,name = "rmnet2";
						iod,ul_buffer_size = <0x800>;
						iod,ul_num_buffers = <0x00>;
					};
				};
			};

			shmem@F0000000 {
				compatible = "samsung,exynos-shm_ipc";
				linux,phandle = <0x34>;
				phandle = <0x34>;
				shmem,cp_size = <0x7900000>;
				shmem,ipc_offset = <0x8000000>;
				shmem,ipc_size = <0x800000>;
				shmem,vss_size = <0x700000>;
			};
		};
	};

	fragment@sound {
		target-path = "/";

		__overlay__ {

			audio_codec_dummy {
				compatible = "snd-soc-dummy";
				linux,phandle = <0x03>;
				phandle = <0x03>;
				status = "okay";
			};

			audio_cpu_dummy {
				compatible = "samsung,dummy-cpu";
				linux,phandle = <0x3c>;
				phandle = <0x3c>;
				status = "okay";
			};

			sound {
				clock-names = "xclkout";
				clocks = <0xffffffff 0x321>;
				compatible = "samsung,exynos9610-audio";
				pinctrl-0 = <0xffffffff>;
				pinctrl-names = "default";
				samsung,aux = <0xffffffff 0xffffffff>;
				samsung,codec = <0xffffffff 0xffffffff 0xffffffff 0xffffffff 0xffffffff 0xffffffff 0xffffffff>;
				samsung,prefix = "ABOX\0ABOX\0ABOX\0ABOX\0ABOX\0ABOX\0ABOX";
				samsung,routing = "HEADSETMIC\0MICBIAS1\0MAINMIC\0MICBIAS2\0SUBMIC\0MICBIAS3\0IN1P\0HEADSETMIC\0IN1N\0HEADSETMIC\0IN3P\0MAINMIC\0IN3N\0MAINMIC\0IN4P\0SUBMIC\0IN4N\0SUBMIC\0RECEIVER\0MONOOUT\0RECEIVER\0MONOOUT\0HEADPHONE\0HPOL\0HEADPHONE\0HPOR\0VOUTPUT\0ABOX UAIF0 Playback\0SPEAKER\0ABOX UAIF2 Playback\0VOUTPUTCALL\0ABOX SIFS0 Playback\0BLUETOOTH SPK\0ABOX SIFS2 Playback\0ABOX SPDY Capture\0FM IN\0ABOX SIFS2 Capture\0BLUETOOTH MIC\0ABOX SIFS0 Capture\0VINPUTCALL";
				status = "okay";

				dsif@0 {
					format = "pdm";

					codec {
						sound-dai = <0x03>;
					};

					cpu {
						sound-dai = <0xffffffff>;
					};
				};

				rdma@0 {

					codec {
						sound-dai = <0x03>;
					};

					cpu {
						sound-dai = <0xffffffff 0x00>;
					};

					platform {
						sound-dai = <0xffffffff>;
					};
				};

				rdma@1 {

					codec {
						sound-dai = <0x03>;
					};

					cpu {
						sound-dai = <0xffffffff 0x01>;
					};

					platform {
						sound-dai = <0xffffffff>;
					};
				};

				rdma@2 {

					codec {
						sound-dai = <0x03>;
					};

					cpu {
						sound-dai = <0xffffffff 0x02>;
					};

					platform {
						sound-dai = <0xffffffff>;
					};
				};

				rdma@3 {

					codec {
						sound-dai = <0x03>;
					};

					cpu {
						sound-dai = <0xffffffff 0x03>;
					};

					platform {
						sound-dai = <0xffffffff>;
					};
				};

				rdma@4 {

					codec {
						sound-dai = <0x03>;
					};

					cpu {
						sound-dai = <0xffffffff 0x04>;
					};

					platform {
						sound-dai = <0xffffffff>;
					};
				};

				rdma@5 {

					codec {
						sound-dai = <0x03>;
					};

					cpu {
						sound-dai = <0xffffffff 0x05>;
					};

					platform {
						sound-dai = <0xffffffff>;
					};
				};

				rdma@6 {

					codec {
						sound-dai = <0x03>;
					};

					cpu {
						sound-dai = <0xffffffff 0x06>;
					};

					platform {
						sound-dai = <0xffffffff>;
					};
				};

				rdma@7 {

					codec {
						sound-dai = <0x03>;
					};

					cpu {
						sound-dai = <0xffffffff 0x07>;
					};

					platform {
						sound-dai = <0xffffffff>;
					};
				};

				sifs0@0 {

					codec {
						sound-dai = <0x03>;
					};

					cpu {
						sound-dai = <0xffffffff 0x0d>;
					};
				};

				sifs1@0 {

					codec {
						sound-dai = <0x03>;
					};

					cpu {
						sound-dai = <0xffffffff 0x0e>;
					};
				};

				sifs2@0 {

					codec {
						sound-dai = <0x03>;
					};

					cpu {
						sound-dai = <0xffffffff 0x0f>;
					};
				};

				spdy@0 {

					codec {
						sound-dai = <0x03>;
					};

					cpu {
						sound-dai = <0xffffffff>;
					};
				};

				uaif@0 {
					format = "i2s";

					codec {
						sound-dai = <0x04 0x00>;
					};

					cpu {
						sound-dai = <0xffffffff>;
					};
				};

				uaif@1 {
					format = "i2s";

					codec {
						sound-dai = <0x03>;
					};

					cpu {
						sound-dai = <0xffffffff>;
					};
				};

				uaif@2 {
					format = "i2s";

					codec {
						sound-dai = <0x05 0x00>;
					};

					cpu {
						sound-dai = <0xffffffff>;
					};

					platform {
						sound-dai = <0xffffffff 0x00>;
					};
				};

				uaif@4 {
					bitclock-master;
					format = "i2s";
					frame-master;

					codec {
						sound-dai = <0x03>;
					};

					cpu {
						sound-dai = <0xffffffff>;
					};
				};

				wdma@0 {

					codec {
						sound-dai = <0x03>;
					};

					cpu {
						sound-dai = <0xffffffff 0x08>;
					};

					platform {
						sound-dai = <0xffffffff>;
					};
				};

				wdma@1 {

					codec {
						sound-dai = <0x03>;
					};

					cpu {
						sound-dai = <0xffffffff 0x09>;
					};

					platform {
						sound-dai = <0xffffffff>;
					};
				};

				wdma@2 {

					codec {
						sound-dai = <0x03>;
					};

					cpu {
						sound-dai = <0xffffffff 0x0a>;
					};

					platform {
						sound-dai = <0xffffffff>;
					};
				};

				wdma@3 {

					codec {
						sound-dai = <0x03>;
					};

					cpu {
						sound-dai = <0xffffffff 0x0b>;
					};

					platform {
						sound-dai = <0xffffffff>;
					};
				};

				wdma@4 {

					codec {
						sound-dai = <0x03>;
					};

					cpu {
						sound-dai = <0xffffffff 0x0c>;
					};

					platform {
						sound-dai = <0xffffffff>;
					};
				};
			};
		};
	};
};
